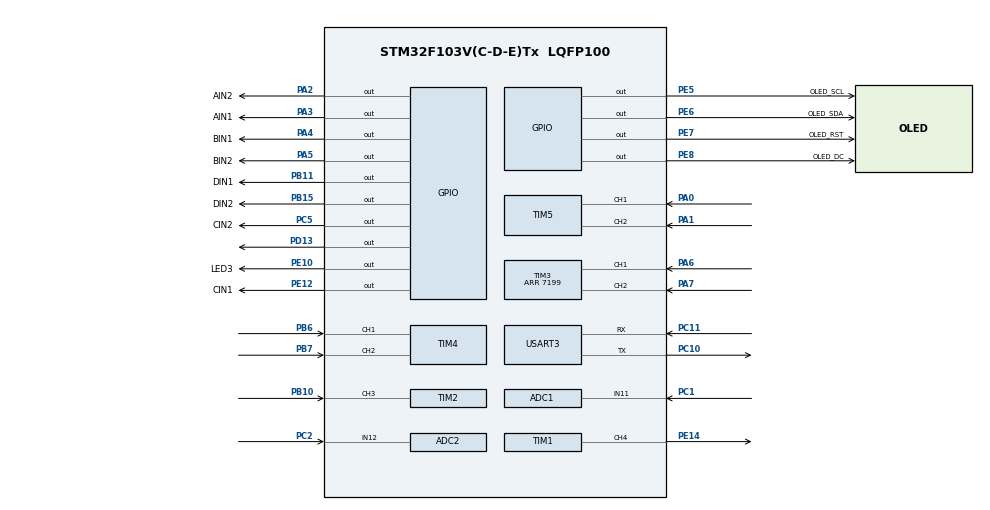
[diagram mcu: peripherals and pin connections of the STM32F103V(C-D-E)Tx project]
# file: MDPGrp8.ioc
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ADC1.Channel-1\#ChannelRegularConversion=ADC_CHANNEL_11
ADC1.NbrOfConversionFlag=1
ADC1.Rank-1\#ChannelRegularConversion=1
ADC1.SamplingTime-1\#ChannelRegularConversion=ADC_SAMPLETIME_1CYCLE_5
ADC1.master=1
ADC2.Channel-0\#ChannelRegularConversion=ADC_CHANNEL_12
ADC2.NbrOfConversionFlag=1
ADC2.Rank-0\#ChannelRegularConversion=1
ADC2.SamplingTime-0\#ChannelRegularConversion=ADC_SAMPLETIME_1CYCLE_5
FREERTOS.Tasks01=defaultTask,24,128,StartDefaultTask,Default,NULL,Dynamic,NULL,NULL;RightMotorTask,8,128,rightmotor,Default,NULL,Dynamic,NULL,NULL;LeftMotorTask,8,128,leftmotor,Default,NULL,Dynamic,NULL,NULL;SensorTask,8,128,sensor,Default,NULL,Dynamic,NULL,NULL
Mcu.Family=STM32F1
Mcu.Name=STM32F103V(C-D-E)Tx
Mcu.Package=LQFP100
NVIC.PriorityGroup=NVIC_PRIORITYGROUP_4
NVIC.TIM2_IRQn=true\:5\:0\:false\:false\:true\:true\:true\:true
NVIC.USART3_IRQn=true\:5\:0\:false\:false\:true\:true\:true\:true
OSC_IN.Mode=HSE-External-Oscillator
OSC_IN.Signal=RCC_OSC_IN
OSC_OUT.Mode=HSE-External-Oscillator
OSC_OUT.Signal=RCC_OSC_OUT
PA0-WKUP.Signal=S_TIM5_CH1
PA1.Signal=S_TIM5_CH2
PA13.Mode=Serial_Wire
PA13.Signal=SYS_JTMS-SWDIO
PA14.Mode=Serial_Wire
PA14.Signal=SYS_JTCK-SWCLK
PA2.GPIO_Label=AIN2
PA2.GPIO_Speed=GPIO_SPEED_FREQ_HIGH
PA2.Signal=GPIO_Output
PA3.GPIO_Label=AIN1
PA3.GPIO_Speed=GPIO_SPEED_FREQ_HIGH
PA3.Signal=GPIO_Output
PA4.GPIO_Label=BIN1
PA4.GPIO_Speed=GPIO_SPEED_FREQ_HIGH
PA4.Signal=GPIO_Output
PA5.GPIO_Label=BIN2
PA5.GPIO_Speed=GPIO_SPEED_FREQ_HIGH
PA5.Signal=GPIO_Output
PA6.Signal=S_TIM3_CH1
PA7.Signal=S_TIM3_CH2
PB10.Signal=S_TIM2_CH3
PB11.GPIO_Label=DIN1
PB11.GPIO_Speed=GPIO_SPEED_FREQ_HIGH
PB11.PinState=GPIO_PIN_RESET
PB11.Signal=GPIO_Output
PB15.GPIO_Label=DIN2
PB15.GPIO_Speed=GPIO_SPEED_FREQ_HIGH
PB15.PinState=GPIO_PIN_RESET
PB15.Signal=GPIO_Output
PB6.Signal=S_TIM4_CH1
PB7.Signal=S_TIM4_CH2
PC1.Signal=ADCx_IN11
PC10.Mode=Asynchronous
PC10.Signal=USART3_TX
PC11.Mode=Asynchronous
PC11.Signal=USART3_RX
PC14-OSC32_IN.Mode=LSE-External-Oscillator
PC14-OSC32_IN.Signal=RCC_OSC32_IN
PC15-OSC32_OUT.Mode=LSE-External-Oscillator
PC15-OSC32_OUT.Signal=RCC_OSC32_OUT
PC2.Signal=ADCx_IN12
PC5.GPIO_Label=CIN2
PC5.GPIO_Speed=GPIO_SPEED_FREQ_HIGH
PC5.Signal=GPIO_Output
PC6.GPIO_Label=TIM8_CH1
PC6.Signal=S_TIM8_CH1
PC7.GPIO_Label=TIM8_CH2
PC7.Signal=S_TIM8_CH2
PC8.Signal=S_TIM8_CH3
PC9.Signal=S_TIM8_CH4
PD13.Signal=GPIO_Output
PE10.GPIO_Label=LED3
PE10.Signal=GPIO_Output
PE12.GPIO_Label=CIN1
PE12.GPIO_Speed=GPIO_SPEED_FREQ_HIGH
PE12.Signal=GPIO_Output
PE14.Signal=S_TIM1_CH4
PE5.GPIO_Label=OLED_SCL
PE5.Signal=GPIO_Output
PE6.GPIO_Label=OLED_SDA
PE6.Signal=GPIO_Output
PE7.GPIO_Label=OLED_RST
PE7.Signal=GPIO_Output
PE8.GPIO_Label=OLED_DC
PE8.Signal=GPIO_Output
ProjectManager.HeapSize=0x200
ProjectManager.StackSize=0x400
ProjectManager.TargetToolchain=STM32CubeIDE
RCC.APB1Freq_Value=8000000
RCC.APB2Freq_Value=8000000
SH.ADCx_IN11.0=ADC1_IN11,IN11
SH.ADCx_IN12.0=ADC2_IN12,IN12
SH.S_TIM1_CH4.0=TIM1_CH4,PWM Generation4 CH4
SH.S_TIM2_CH3.0=TIM2_CH3,Input_Capture3_from_TI3
SH.S_TIM3_CH1.0=TIM3_CH1,Encoder_Interface
SH.S_TIM3_CH2.0=TIM3_CH2,Encoder_Interface
SH.S_TIM4_CH1.0=TIM4_CH1,Encoder_Interface
SH.S_TIM4_CH2.0=TIM4_CH2,Encoder_Interface
SH.S_TIM5_CH1.0=TIM5_CH1,Encoder_Interface
SH.S_TIM5_CH2.0=TIM5_CH2,Encoder_Interface
SH.S_TIM8_CH1.0=TIM8_CH1
SH.S_TIM8_CH2.0=TIM8_CH2
SH.S_TIM8_CH3.0=TIM8_CH3
SH.S_TIM8_CH4.0=TIM8_CH4
TIM1.AutoReloadPreload=TIM_AUTORELOAD_PRELOAD_ENABLE
TIM1.Channel-PWM\ Generation4\ CH4=TIM_CHANNEL_4
TIM1.Period=1000
TIM1.Prescaler=160
TIM2.Channel-Input_Capture3_from_TI3=TIM_CHANNEL_3
TIM2.Period=0xffff-1
TIM2.Prescaler=8-1
TIM3.EncoderMode=TIM_ENCODERMODE_TI12
TIM3.IC1Filter=10
TIM3.IC2Filter=10
TIM3.Period=7199
TIM4.EncoderMode=TIM_ENCODERMODE_TI12
TIM4.IC1Filter=10
TIM4.IC2Filter=10
TIM5.EncoderMode=TIM_ENCODERMODE_TI12
TIM5.IC1Filter=10
TIM5.IC2Filter=10
TIM8.Channel-PWM\ Generation1\ No\ Output=TIM_CHANNEL_1
TIM8.Channel-PWM\ Generation2\ No\ Output=TIM_CHANNEL_2
TIM8.Channel-PWM\ Generation3\ No\ Output=TIM_CHANNEL_3
TIM8.Channel-PWM\ Generation4\ No\ Output=TIM_CHANNEL_4
TIM8.Period=7199
USART3.VirtualMode=VM_ASYNC
VP_FREERTOS_VS_CMSIS_V2.Mode=CMSIS_V2
VP_TIM1_VS_ClockSourceINT.Mode=Internal
VP_TIM8_VS_ClockSourceINT.Mode=Internal
VP_TIM8_VS_no_output1.Mode=PWM Generation1 No Output
VP_TIM8_VS_no_output2.Mode=PWM Generation2 No Output
VP_TIM8_VS_no_output3.Mode=PWM Generation3 No Output
VP_TIM8_VS_no_output4.Mode=PWM Generation4 No Output
board=custom

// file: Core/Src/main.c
/* USER CODE BEGIN Header */
/**
  ******************************************************************************
  * @file           : main.c
  * @brief          : Main program body
  ******************************************************************************
  * @attention
  *
  * <h2><center>&copy; Copyright (c) 2021 STMicroelectronics.
  * All rights reserved.</center></h2>
  *
  * This software component is licensed by ST under BSD 3-Clause license,
  * the "License"; You may not use this file except in compliance with the
  * License. You may obtain a copy of the License at:
  *                        opensource.org/licenses/BSD-3-Clause
  *
  ******************************************************************************
  */
/* USER CODE END Header */
#include "main.h"
#include "cmsis_os.h"
#include "oled.h"
#include "stdio.h"

ADC_HandleTypeDef hadc1;
ADC_HandleTypeDef hadc2;

TIM_HandleTypeDef htim1;
TIM_HandleTypeDef htim2;
TIM_HandleTypeDef htim3;
TIM_HandleTypeDef htim4;
TIM_HandleTypeDef htim5;
TIM_HandleTypeDef htim8;

UART_HandleTypeDef huart3;

/* Definitions for defaultTask */
osThreadId_t defaultTaskHandle;
const osThreadAttr_t defaultTask_attributes = {
  .name = "defaultTask",
  .stack_size = 128 * 4,
  .priority = (osPriority_t) osPriorityNormal,
};
/* Definitions for RightMotorTask */
osThreadId_t RightMotorTaskHandle;
const osThreadAttr_t RightMotorTask_attributes = {
  .name = "RightMotorTask",
  .stack_size = 128 * 4,
  .priority = (osPriority_t) osPriorityLow,
};
/* Definitions for LeftMotorTask */
osThreadId_t LeftMotorTaskHandle;
const osThreadAttr_t LeftMotorTask_attributes = {
  .name = "LeftMotorTask",
  .stack_size = 128 * 4,
  .priority = (osPriority_t) osPriorityLow,
};
/* Definitions for SensorTask */
osThreadId_t SensorTaskHandle;
const osThreadAttr_t SensorTask_attributes = {
  .name = "SensorTask",
  .stack_size = 128 * 4,
  .priority = (osPriority_t) osPriorityLow,
};

void SystemClock_Config(void);
static void MX_GPIO_Init(void);
static void MX_TIM8_Init(void);
static void MX_TIM2_Init(void);
static void MX_TIM3_Init(void);
static void MX_TIM1_Init(void);
static void MX_USART3_UART_Init(void);
static void MX_TIM4_Init(void);
static void MX_TIM5_Init(void);
static void MX_ADC1_Init(void);
static void MX_ADC2_Init(void);
void StartDefaultTask(void *argument);
void rightmotor(void *argument);
void leftmotor(void *argument);
void sensor(void *argument);

/* USER CODE BEGIN 0 */
uint8_t aRxBuffer[5];
uint8_t value[5];
uint8_t home[5];
uint8_t stopwheel=0;
uint8_t sensordist;
uint8_t move5;
/* USER CODE END 0 */
void delay (uint16_t time)
{
	__HAL_TIM_SET_COUNTER(&htim2,0);
	while(__HAL_TIM_GET_COUNTER (&htim2)< time);
}

uint32_t IC_Val1 = 0;
uint32_t IC_Val2 = 0;
uint32_t Difference = 0;
uint8_t Is_First_Captured = 0;  // is the first value captured ?
uint8_t Distance  = 0;

#define TRIG_PIN GPIO_PIN_13
#define TRIG_PORT GPIOD

// Let's write the callback function

void HAL_TIM_IC_CaptureCallback(TIM_HandleTypeDef *htim)
{
	if (htim->Channel == HAL_TIM_ACTIVE_CHANNEL_3)  // if the interrupt source is channel1
	{
		if (Is_First_Captured==0) // if the first value is not captured
		{
			IC_Val1 = HAL_TIM_ReadCapturedValue(htim, TIM_CHANNEL_3); // read the first value
			Is_First_Captured = 1;  // set the first captured as true
			// Now change the polarity to falling edge
			__HAL_TIM_SET_CAPTUREPOLARITY(htim, TIM_CHANNEL_3, TIM_INPUTCHANNELPOLARITY_FALLING);
		}

		else if (Is_First_Captured==1)   // if the first is already captured
		{
			IC_Val2 = HAL_TIM_ReadCapturedValue(htim, TIM_CHANNEL_3);  // read second value
			__HAL_TIM_SET_COUNTER(htim, 0);  // reset the counter

			if (IC_Val2 > IC_Val1)
			{
				Difference = IC_Val2-IC_Val1;
			}

			else if (IC_Val1 > IC_Val2)
			{
				Difference = (0xffff - IC_Val1) + IC_Val2;
			}

			Distance = Difference * .034/2;
			Is_First_Captured = 0; // set it back to false

			// set polarity to rising edge
			__HAL_TIM_SET_CAPTUREPOLARITY(htim, TIM_CHANNEL_3, TIM_INPUTCHANNELPOLARITY_RISING);
			__HAL_TIM_DISABLE_IT(&htim2, TIM_IT_CC1);
		}
	}
}

void HCSR04_Read (void)
{
	HAL_GPIO_WritePin(TRIG_PORT, TRIG_PIN, GPIO_PIN_SET);  // pull the TRIG pin HIGH
	delay(10);  // wait for 10 us
	HAL_GPIO_WritePin(TRIG_PORT, TRIG_PIN, GPIO_PIN_RESET);  // pull the TRIG pin low

	__HAL_TIM_ENABLE_IT(&htim2, TIM_IT_CC1);
}
int main(void)
{

  /* MCU Configuration--------------------------------------------------------*/

  /* Reset of all peripherals, Initializes the Flash interface and the Systick. */
  HAL_Init();

  /* Configure the system clock */
  SystemClock_Config();

  /* Initialize all configured peripherals */
  MX_GPIO_Init();
  MX_TIM8_Init();
  MX_TIM2_Init();
  MX_TIM3_Init();
  MX_TIM1_Init();
  MX_USART3_UART_Init();
  MX_TIM4_Init();
  MX_TIM5_Init();
  MX_ADC1_Init();
  MX_ADC2_Init();
  /* USER CODE BEGIN 2 */
  OLED_Init();
  /* USER CODE END 2 */

  /* Init scheduler */
  osKernelInitialize();

  /* Create the thread(s) */
  /* creation of defaultTask */
  defaultTaskHandle = osThreadNew(StartDefaultTask, NULL, &defaultTask_attributes);

  /* creation of RightMotorTask */
  RightMotorTaskHandle = osThreadNew(rightmotor, NULL, &RightMotorTask_attributes);

  /* creation of LeftMotorTask */
  LeftMotorTaskHandle = osThreadNew(leftmotor, NULL, &LeftMotorTask_attributes);

  /* creation of SensorTask */
  SensorTaskHandle = osThreadNew(sensor, NULL, &SensorTask_attributes);

  /* Start scheduler */
  osKernelStart();

  /* We should never get here as control is now taken by the scheduler */
  /* Infinite loop */
  while (1)
  {

  }
}

void SystemClock_Config(void)
{
  RCC_OscInitTypeDef RCC_OscInitStruct = {0};
  RCC_ClkInitTypeDef RCC_ClkInitStruct = {0};
  RCC_PeriphCLKInitTypeDef PeriphClkInit = {0};

  /** Initializes the RCC Oscillators according to the specified parameters
  * in the RCC_OscInitTypeDef structure.
  */
  RCC_OscInitStruct.OscillatorType = RCC_OSCILLATORTYPE_HSI;
  RCC_OscInitStruct.HSIState = RCC_HSI_ON;
  RCC_OscInitStruct.HSICalibrationValue = RCC_HSICALIBRATION_DEFAULT;
  RCC_OscInitStruct.PLL.PLLState = RCC_PLL_NONE;
  if (HAL_RCC_OscConfig(&RCC_OscInitStruct) != HAL_OK)
  {
    Error_Handler();
  }
  /** Initializes the CPU, AHB and APB buses clocks
  */
  RCC_ClkInitStruct.ClockType = RCC_CLOCKTYPE_HCLK|RCC_CLOCKTYPE_SYSCLK
                              |RCC_CLOCKTYPE_PCLK1|RCC_CLOCKTYPE_PCLK2;
  RCC_ClkInitStruct.SYSCLKSource = RCC_SYSCLKSOURCE_HSI;
  RCC_ClkInitStruct.AHBCLKDivider = RCC_SYSCLK_DIV1;
  RCC_ClkInitStruct.APB1CLKDivider = RCC_HCLK_DIV1;
  RCC_ClkInitStruct.APB2CLKDivider = RCC_HCLK_DIV1;

  if (HAL_RCC_ClockConfig(&RCC_ClkInitStruct, FLASH_LATENCY_0) != HAL_OK)
  {
    Error_Handler();
  }
  PeriphClkInit.PeriphClockSelection = RCC_PERIPHCLK_ADC;
  PeriphClkInit.AdcClockSelection = RCC_ADCPCLK2_DIV2;
  if (HAL_RCCEx_PeriphCLKConfig(&PeriphClkInit) != HAL_OK)
  {
    Error_Handler();
  }
}

static void MX_ADC1_Init(void)
{

  ADC_ChannelConfTypeDef sConfig = {0};

  /** Common config
  */
  hadc1.Instance = ADC1;
  hadc1.Init.ScanConvMode = ADC_SCAN_DISABLE;
  hadc1.Init.ContinuousConvMode = DISABLE;
  hadc1.Init.DiscontinuousConvMode = DISABLE;
  hadc1.Init.ExternalTrigConv = ADC_SOFTWARE_START;
  hadc1.Init.DataAlign = ADC_DATAALIGN_RIGHT;
  hadc1.Init.NbrOfConversion = 1;
  if (HAL_ADC_Init(&hadc1) != HAL_OK)
  {
    Error_Handler();
  }
  /** Configure Regular Channel
  */
  sConfig.Channel = ADC_CHANNEL_11;
  sConfig.Rank = ADC_REGULAR_RANK_1;
  sConfig.SamplingTime = ADC_SAMPLETIME_1CYCLE_5;
  if (HAL_ADC_ConfigChannel(&hadc1, &sConfig) != HAL_OK)
  {
    Error_Handler();
  }

}

static void MX_ADC2_Init(void)
{

  ADC_ChannelConfTypeDef sConfig = {0};

  /** Common config
  */
  hadc2.Instance = ADC2;
  hadc2.Init.ScanConvMode = ADC_SCAN_DISABLE;
  hadc2.Init.ContinuousConvMode = DISABLE;
  hadc2.Init.DiscontinuousConvMode = DISABLE;
  hadc2.Init.ExternalTrigConv = ADC_SOFTWARE_START;
  hadc2.Init.DataAlign = ADC_DATAALIGN_RIGHT;
  hadc2.Init.NbrOfConversion = 1;
  if (HAL_ADC_Init(&hadc2) != HAL_OK)
  {
    Error_Handler();
  }
  /** Configure Regular Channel
  */
  sConfig.Channel = ADC_CHANNEL_12;
  sConfig.Rank = ADC_REGULAR_RANK_1;
  sConfig.SamplingTime = ADC_SAMPLETIME_1CYCLE_5;
  if (HAL_ADC_ConfigChannel(&hadc2, &sConfig) != HAL_OK)
  {
    Error_Handler();
  }

}

static void MX_TIM1_Init(void)
{

  TIM_ClockConfigTypeDef sClockSourceConfig = {0};
  TIM_MasterConfigTypeDef sMasterConfig = {0};
  TIM_OC_InitTypeDef sConfigOC = {0};
  TIM_BreakDeadTimeConfigTypeDef sBreakDeadTimeConfig = {0};

  htim1.Instance = TIM1;
  htim1.Init.Prescaler = 160;
  htim1.Init.CounterMode = TIM_COUNTERMODE_UP;
  htim1.Init.Period = 1000;
  htim1.Init.ClockDivision = TIM_CLOCKDIVISION_DIV1;
  htim1.Init.RepetitionCounter = 0;
  htim1.Init.AutoReloadPreload = TIM_AUTORELOAD_PRELOAD_ENABLE;
  if (HAL_TIM_Base_Init(&htim1) != HAL_OK)
  {
    Error_Handler();
  }
  sClockSourceConfig.ClockSource = TIM_CLOCKSOURCE_INTERNAL;
  if (HAL_TIM_ConfigClockSource(&htim1, &sClockSourceConfig) != HAL_OK)
  {
    Error_Handler();
  }
  if (HAL_TIM_PWM_Init(&htim1) != HAL_OK)
  {
    Error_Handler();
  }
  sMasterConfig.MasterOutputTrigger = TIM_TRGO_RESET;
  sMasterConfig.MasterSlaveMode = TIM_MASTERSLAVEMODE_DISABLE;
  if (HAL_TIMEx_MasterConfigSynchronization(&htim1, &sMasterConfig) != HAL_OK)
  {
    Error_Handler();
  }
  sConfigOC.OCMode = TIM_OCMODE_PWM1;
  sConfigOC.Pulse = 0;
  sConfigOC.OCPolarity = TIM_OCPOLARITY_HIGH;
  sConfigOC.OCFastMode = TIM_OCFAST_DISABLE;
  sConfigOC.OCIdleState = TIM_OCIDLESTATE_RESET;
  sConfigOC.OCNIdleState = TIM_OCNIDLESTATE_RESET;
  if (HAL_TIM_PWM_ConfigChannel(&htim1, &sConfigOC, TIM_CHANNEL_4) != HAL_OK)
  {
    Error_Handler();
  }
  sBreakDeadTimeConfig.OffStateRunMode = TIM_OSSR_DISABLE;
  sBreakDeadTimeConfig.OffStateIDLEMode = TIM_OSSI_DISABLE;
  sBreakDeadTimeConfig.LockLevel = TIM_LOCKLEVEL_OFF;
  sBreakDeadTimeConfig.DeadTime = 0;
  sBreakDeadTimeConfig.BreakState = TIM_BREAK_DISABLE;
  sBreakDeadTimeConfig.BreakPolarity = TIM_BREAKPOLARITY_HIGH;
  sBreakDeadTimeConfig.AutomaticOutput = TIM_AUTOMATICOUTPUT_DISABLE;
  if (HAL_TIMEx_ConfigBreakDeadTime(&htim1, &sBreakDeadTimeConfig) != HAL_OK)
  {
    Error_Handler();
  }
  HAL_TIM_MspPostInit(&htim1);

}

static void MX_TIM2_Init(void)
{

  TIM_MasterConfigTypeDef sMasterConfig = {0};
  TIM_IC_InitTypeDef sConfigIC = {0};

  htim2.Instance = TIM2;
  htim2.Init.Prescaler = 8-1;
  htim2.Init.CounterMode = TIM_COUNTERMODE_UP;
  htim2.Init.Period = 0xffff-1;
  htim2.Init.ClockDivision = TIM_CLOCKDIVISION_DIV1;
  htim2.Init.AutoReloadPreload = TIM_AUTORELOAD_PRELOAD_DISABLE;
  if (HAL_TIM_IC_Init(&htim2) != HAL_OK)
  {
    Error_Handler();
  }
  sMasterConfig.MasterOutputTrigger = TIM_TRGO_RESET;
  sMasterConfig.MasterSlaveMode = TIM_MASTERSLAVEMODE_DISABLE;
  if (HAL_TIMEx_MasterConfigSynchronization(&htim2, &sMasterConfig) != HAL_OK)
  {
    Error_Handler();
  }
  sConfigIC.ICPolarity = TIM_INPUTCHANNELPOLARITY_RISING;
  sConfigIC.ICSelection = TIM_ICSELECTION_DIRECTTI;
  sConfigIC.ICPrescaler = TIM_ICPSC_DIV1;
  sConfigIC.ICFilter = 0;
  if (HAL_TIM_IC_ConfigChannel(&htim2, &sConfigIC, TIM_CHANNEL_3) != HAL_OK)
  {
    Error_Handler();
  }

}

static void MX_TIM3_Init(void)
{

  TIM_Encoder_InitTypeDef sConfig = {0};
  TIM_MasterConfigTypeDef sMasterConfig = {0};

  htim3.Instance = TIM3;
  htim3.Init.Prescaler = 0;
  htim3.Init.CounterMode = TIM_COUNTERMODE_UP;
  htim3.Init.Period = 7199;
  htim3.Init.ClockDivision = TIM_CLOCKDIVISION_DIV1;
  htim3.Init.AutoReloadPreload = TIM_AUTORELOAD_PRELOAD_DISABLE;
  sConfig.EncoderMode = TIM_ENCODERMODE_TI12;
  sConfig.IC1Polarity = TIM_ICPOLARITY_RISING;
  sConfig.IC1Selection = TIM_ICSELECTION_DIRECTTI;
  sConfig.IC1Prescaler = TIM_ICPSC_DIV1;
  sConfig.IC1Filter = 10;
  sConfig.IC2Polarity = TIM_ICPOLARITY_RISING;
  sConfig.IC2Selection = TIM_ICSELECTION_DIRECTTI;
  sConfig.IC2Prescaler = TIM_ICPSC_DIV1;
  sConfig.IC2Filter = 10;
  if (HAL_TIM_Encoder_Init(&htim3, &sConfig) != HAL_OK)
  {
    Error_Handler();
  }
  sMasterConfig.MasterOutputTrigger = TIM_TRGO_RESET;
  sMasterConfig.MasterSlaveMode = TIM_MASTERSLAVEMODE_DISABLE;
  if (HAL_TIMEx_MasterConfigSynchronization(&htim3, &sMasterConfig) != HAL_OK)
  {
    Error_Handler();
  }

}

static void MX_TIM4_Init(void)
{

  TIM_Encoder_InitTypeDef sConfig = {0};
  TIM_MasterConfigTypeDef sMasterConfig = {0};

  htim4.Instance = TIM4;
  htim4.Init.Prescaler = 0;
  htim4.Init.CounterMode = TIM_COUNTERMODE_UP;
  htim4.Init.Period = 65535;
  htim4.Init.ClockDivision = TIM_CLOCKDIVISION_DIV1;
  htim4.Init.AutoReloadPreload = TIM_AUTORELOAD_PRELOAD_DISABLE;
  sConfig.EncoderMode = TIM_ENCODERMODE_TI12;
  sConfig.IC1Polarity = TIM_ICPOLARITY_RISING;
  sConfig.IC1Selection = TIM_ICSELECTION_DIRECTTI;
  sConfig.IC1Prescaler = TIM_ICPSC_DIV1;
  sConfig.IC1Filter = 10;
  sConfig.IC2Polarity = TIM_ICPOLARITY_RISING;
  sConfig.IC2Selection = TIM_ICSELECTION_DIRECTTI;
  sConfig.IC2Prescaler = TIM_ICPSC_DIV1;
  sConfig.IC2Filter = 10;
  if (HAL_TIM_Encoder_Init(&htim4, &sConfig) != HAL_OK)
  {
    Error_Handler();
  }
  sMasterConfig.MasterOutputTrigger = TIM_TRGO_RESET;
  sMasterConfig.MasterSlaveMode = TIM_MASTERSLAVEMODE_DISABLE;
  if (HAL_TIMEx_MasterConfigSynchronization(&htim4, &sMasterConfig) != HAL_OK)
  {
    Error_Handler();
  }

}

static void MX_TIM5_Init(void)
{

  TIM_Encoder_InitTypeDef sConfig = {0};
  TIM_MasterConfigTypeDef sMasterConfig = {0};

  htim5.Instance = TIM5;
  htim5.Init.Prescaler = 0;
  htim5.Init.CounterMode = TIM_COUNTERMODE_UP;
  htim5.Init.Period = 65535;
  htim5.Init.ClockDivision = TIM_CLOCKDIVISION_DIV1;
  htim5.Init.AutoReloadPreload = TIM_AUTORELOAD_PRELOAD_DISABLE;
  sConfig.EncoderMode = TIM_ENCODERMODE_TI12;
  sConfig.IC1Polarity = TIM_ICPOLARITY_RISING;
  sConfig.IC1Selection = TIM_ICSELECTION_DIRECTTI;
  sConfig.IC1Prescaler = TIM_ICPSC_DIV1;
  sConfig.IC1Filter = 10;
  sConfig.IC2Polarity = TIM_ICPOLARITY_RISING;
  sConfig.IC2Selection = TIM_ICSELECTION_DIRECTTI;
  sConfig.IC2Prescaler = TIM_ICPSC_DIV1;
  sConfig.IC2Filter = 10;
  if (HAL_TIM_Encoder_Init(&htim5, &sConfig) != HAL_OK)
  {
    Error_Handler();
  }
  sMasterConfig.MasterOutputTrigger = TIM_TRGO_RESET;
  sMasterConfig.MasterSlaveMode = TIM_MASTERSLAVEMODE_DISABLE;
  if (HAL_TIMEx_MasterConfigSynchronization(&htim5, &sMasterConfig) != HAL_OK)
  {
    Error_Handler();
  }

}

static void MX_TIM8_Init(void)
{

  TIM_ClockConfigTypeDef sClockSourceConfig = {0};
  TIM_MasterConfigTypeDef sMasterConfig = {0};
  TIM_OC_InitTypeDef sConfigOC = {0};
  TIM_BreakDeadTimeConfigTypeDef sBreakDeadTimeConfig = {0};

  htim8.Instance = TIM8;
  htim8.Init.Prescaler = 0;
  htim8.Init.CounterMode = TIM_COUNTERMODE_UP;
  htim8.Init.Period = 7199;
  htim8.Init.ClockDivision = TIM_CLOCKDIVISION_DIV1;
  htim8.Init.RepetitionCounter = 0;
  htim8.Init.AutoReloadPreload = TIM_AUTORELOAD_PRELOAD_DISABLE;
  if (HAL_TIM_Base_Init(&htim8) != HAL_OK)
  {
    Error_Handler();
  }
  sClockSourceConfig.ClockSource = TIM_CLOCKSOURCE_INTERNAL;
  if (HAL_TIM_ConfigClockSource(&htim8, &sClockSourceConfig) != HAL_OK)
  {
    Error_Handler();
  }
  if (HAL_TIM_PWM_Init(&htim8) != HAL_OK)
  {
    Error_Handler();
  }
  sMasterConfig.MasterOutputTrigger = TIM_TRGO_RESET;
  sMasterConfig.MasterSlaveMode = TIM_MASTERSLAVEMODE_DISABLE;
  if (HAL_TIMEx_MasterConfigSynchronization(&htim8, &sMasterConfig) != HAL_OK)
  {
    Error_Handler();
  }
  sConfigOC.OCMode = TIM_OCMODE_PWM1;
  sConfigOC.Pulse = 0;
  sConfigOC.OCPolarity = TIM_OCPOLARITY_HIGH;
  sConfigOC.OCNPolarity = TIM_OCNPOLARITY_HIGH;
  sConfigOC.OCFastMode = TIM_OCFAST_DISABLE;
  sConfigOC.OCIdleState = TIM_OCIDLESTATE_RESET;
  sConfigOC.OCNIdleState = TIM_OCNIDLESTATE_RESET;
  if (HAL_TIM_PWM_ConfigChannel(&htim8, &sConfigOC, TIM_CHANNEL_1) != HAL_OK)
  {
    Error_Handler();
  }
  if (HAL_TIM_PWM_ConfigChannel(&htim8, &sConfigOC, TIM_CHANNEL_2) != HAL_OK)
  {
    Error_Handler();
  }
  if (HAL_TIM_PWM_ConfigChannel(&htim8, &sConfigOC, TIM_CHANNEL_3) != HAL_OK)
  {
    Error_Handler();
  }
  if (HAL_TIM_PWM_ConfigChannel(&htim8, &sConfigOC, TIM_CHANNEL_4) != HAL_OK)
  {
    Error_Handler();
  }
  sBreakDeadTimeConfig.OffStateRunMode = TIM_OSSR_DISABLE;
  sBreakDeadTimeConfig.OffStateIDLEMode = TIM_OSSI_DISABLE;
  sBreakDeadTimeConfig.LockLevel = TIM_LOCKLEVEL_OFF;
  sBreakDeadTimeConfig.DeadTime = 0;
  sBreakDeadTimeConfig.BreakState = TIM_BREAK_DISABLE;
  sBreakDeadTimeConfig.BreakPolarity = TIM_BREAKPOLARITY_HIGH;
  sBreakDeadTimeConfig.AutomaticOutput = TIM_AUTOMATICOUTPUT_DISABLE;
  if (HAL_TIMEx_ConfigBreakDeadTime(&htim8, &sBreakDeadTimeConfig) != HAL_OK)
  {
    Error_Handler();
  }

}

static void MX_USART3_UART_Init(void)
{

  huart3.Instance = USART3;
  huart3.Init.BaudRate = 115200;
  huart3.Init.WordLength = UART_WORDLENGTH_8B;
  huart3.Init.StopBits = UART_STOPBITS_1;
  huart3.Init.Parity = UART_PARITY_NONE;
  huart3.Init.Mode = UART_MODE_TX_RX;
  huart3.Init.HwFlowCtl = UART_HWCONTROL_NONE;
  huart3.Init.OverSampling = UART_OVERSAMPLING_16;
  if (HAL_UART_Init(&huart3) != HAL_OK)
  {
    Error_Handler();
  }

}

static void MX_GPIO_Init(void)
{
  GPIO_InitTypeDef GPIO_InitStruct = {0};

  /* GPIO Ports Clock Enable */
  __HAL_RCC_GPIOE_CLK_ENABLE();
  __HAL_RCC_GPIOC_CLK_ENABLE();
  __HAL_RCC_GPIOA_CLK_ENABLE();
  __HAL_RCC_GPIOB_CLK_ENABLE();
  __HAL_RCC_GPIOD_CLK_ENABLE();

  /*Configure GPIO pin Output Level */
  HAL_GPIO_WritePin(GPIOE, OLED_SCL_Pin|OLED_SDA_Pin|OLED_RST_Pin|OLED_DC_Pin
                          |LED3_Pin|CIN1_Pin, GPIO_PIN_RESET);

  /*Configure GPIO pin Output Level */
  HAL_GPIO_WritePin(GPIOA, AIN2_Pin|AIN1_Pin|BIN1_Pin|BIN2_Pin, GPIO_PIN_RESET);

  /*Configure GPIO pin Output Level */
  HAL_GPIO_WritePin(CIN2_GPIO_Port, CIN2_Pin, GPIO_PIN_RESET);

  /*Configure GPIO pin Output Level */
  HAL_GPIO_WritePin(GPIOB, DIN1_Pin|DIN2_Pin, GPIO_PIN_RESET);

  /*Configure GPIO pin Output Level */
  HAL_GPIO_WritePin(GPIOD, GPIO_PIN_13, GPIO_PIN_RESET);

  /*Configure GPIO pins : OLED_SCL_Pin OLED_SDA_Pin OLED_RST_Pin OLED_DC_Pin
                           LED3_Pin */
  GPIO_InitStruct.Pin = OLED_SCL_Pin|OLED_SDA_Pin|OLED_RST_Pin|OLED_DC_Pin
                          |LED3_Pin;
  GPIO_InitStruct.Mode = GPIO_MODE_OUTPUT_PP;
  GPIO_InitStruct.Pull = GPIO_NOPULL;
  GPIO_InitStruct.Speed = GPIO_SPEED_FREQ_LOW;
  HAL_GPIO_Init(GPIOE, &GPIO_InitStruct);

  /*Configure GPIO pins : AIN2_Pin AIN1_Pin BIN1_Pin BIN2_Pin */
  GPIO_InitStruct.Pin = AIN2_Pin|AIN1_Pin|BIN1_Pin|BIN2_Pin;
  GPIO_InitStruct.Mode = GPIO_MODE_OUTPUT_PP;
  GPIO_InitStruct.Pull = GPIO_NOPULL;
  GPIO_InitStruct.Speed = GPIO_SPEED_FREQ_HIGH;
  HAL_GPIO_Init(GPIOA, &GPIO_InitStruct);

  /*Configure GPIO pin : CIN2_Pin */
  GPIO_InitStruct.Pin = CIN2_Pin;
  GPIO_InitStruct.Mode = GPIO_MODE_OUTPUT_PP;
  GPIO_InitStruct.Pull = GPIO_NOPULL;
  GPIO_InitStruct.Speed = GPIO_SPEED_FREQ_HIGH;
  HAL_GPIO_Init(CIN2_GPIO_Port, &GPIO_InitStruct);

  /*Configure GPIO pin : CIN1_Pin */
  GPIO_InitStruct.Pin = CIN1_Pin;
  GPIO_InitStruct.Mode = GPIO_MODE_OUTPUT_PP;
  GPIO_InitStruct.Pull = GPIO_NOPULL;
  GPIO_InitStruct.Speed = GPIO_SPEED_FREQ_HIGH;
  HAL_GPIO_Init(CIN1_GPIO_Port, &GPIO_InitStruct);

  /*Configure GPIO pins : DIN1_Pin DIN2_Pin */
  GPIO_InitStruct.Pin = DIN1_Pin|DIN2_Pin;
  GPIO_InitStruct.Mode = GPIO_MODE_OUTPUT_PP;
  GPIO_InitStruct.Pull = GPIO_NOPULL;
  GPIO_InitStruct.Speed = GPIO_SPEED_FREQ_HIGH;
  HAL_GPIO_Init(GPIOB, &GPIO_InitStruct);

  /*Configure GPIO pin : PD13 */
  GPIO_InitStruct.Pin = GPIO_PIN_13;
  GPIO_InitStruct.Mode = GPIO_MODE_OUTPUT_PP;
  GPIO_InitStruct.Pull = GPIO_NOPULL;
  GPIO_InitStruct.Speed = GPIO_SPEED_FREQ_LOW;
  HAL_GPIO_Init(GPIOD, &GPIO_InitStruct);

}

/* USER CODE BEGIN 4 */
void HAL_UART_RxCpltCallback(UART_HandleTypeDef *huart)
{
	UNUSED(huart);

	//HAL_UART_Transmit(&huart3, (uint8_t *)aRxBuffer,12,0xFFFF);
}
/* USER CODE END 4 */

void StartDefaultTask(void *argument)
{
  /* USER CODE BEGIN 5 */
  /* Infinite loop */
	uint8_t hello[20]="Hello World!\0";

	HAL_TIM_PWM_Start(&htim1,TIM_CHANNEL_4);
	uint8_t ch='A';
	sprintf(value,"%s\0","00000");
	int wk9task=0;

	uint8_t temp[5];
  for(;;)
  {	/*
	  htim1.Instance->CCR4=85;//right
	  osDelay(5000);
	  htim1.Instance->CCR4=72;//center
	  osDelay(5000);
	  htim1.Instance->CCR4=60;//left
	  osDelay(5000);
	  htim1.Instance->CCR4=72;//center
	  osDelay(5000);
	*/
	HAL_UART_Receive_IT(&huart3,(uint8_t *) aRxBuffer,5);
	OLED_ShowString(10,10,hello);
	sprintf(value,"%s\0",aRxBuffer);
	OLED_ShowString(10,40,value);
	HAL_GPIO_TogglePin(LED3_GPIO_Port,LED3_Pin);
	OLED_Refresh_Gram();
	osDelay(500);

  }
  /* USER CODE END 5 */
}

void rightmotor(void *argument)
{
  /* USER CODE BEGIN rightmotor */
  /* Infinite loop */
	uint16_t pwmVal=2900;
	HAL_TIM_PWM_Start(&htim8,TIM_CHANNEL_4);
	int x;
	uint8_t flag=1;

	uint32_t val=0;
	val=1.25*750;
	int backdistance;
	HAL_TIM_Encoder_Start(&htim5,TIM_CHANNEL_ALL);
	int cnt1,cnt2,diff;
	uint32_t tick;
	uint16_t dir;
	uint32_t tickbaseval=520;
	uint32_t totaldist=0;
	uint32_t dist=0;
	uint32_t temp;
	uint8_t hello[20];
	for(;;)
	{

		x=atoi(value);
		dist = (uint32_t)(x%1000); //Get last 2 Digit
		x/=1000;
		switch(x) {
			case 30	:

				totaldist=0;
				diff=0;
				cnt1=__HAL_TIM_GET_COUNTER(&htim5);
				htim1.Instance->CCR4=74;
				HAL_GPIO_WritePin(GPIOB, DIN2_Pin, GPIO_PIN_SET);
				HAL_GPIO_WritePin(GPIOB, DIN1_Pin, GPIO_PIN_RESET);
				__HAL_TIM_SetCompare(&htim8, TIM_CHANNEL_4, pwmVal);
				tick=HAL_GetTick();
				temp=sensordist/10;
				backdistance=temp;
				temp=tickbaseval*(temp-5);
				if(backdistance>=8)
				{
					while(totaldist<temp)
					{
//						if(sensordist<=37)
//						{
//							break;
//						}
						if(HAL_GetTick()-tick>25L)
						{
							cnt2=__HAL_TIM_GET_COUNTER(&htim5);
							if(__HAL_TIM_IS_TIM_COUNTING_DOWN(&htim5))
							{
								if(cnt2<cnt1)
									diff=cnt1-cnt2;
								else
									diff=(65535-cnt2)+cnt1;
							}
							else
							{
								if(cnt2>cnt1)
									diff=cnt2-cnt1;
								else
									diff=(65535-cnt1)+cnt2;
							}

							sprintf(hello, "S:%5d\0", diff);
							OLED_ShowString(50,30,hello);
							dir = __HAL_TIM_IS_TIM_COUNTING_DOWN(&htim5);
							sprintf(hello, "RD:%2d\0", dir);
							OLED_ShowString(10,30,hello);
							cnt1=__HAL_TIM_GET_COUNTER(&htim5);
							tick=HAL_GetTick();
							totaldist+=diff;
						}

					}
				}
				else
				{
					while(totaldist<temp)
					{
						if(sensordist<=37)
						{
							break;
						}
						if(HAL_GetTick()-tick>25L)
						{
							cnt2=__HAL_TIM_GET_COUNTER(&htim5);
							if(__HAL_TIM_IS_TIM_COUNTING_DOWN(&htim5))
							{
								if(cnt2<cnt1)
									diff=cnt1-cnt2;
								else
									diff=(65535-cnt2)+cnt1;
							}
							else
							{
								if(cnt2>cnt1)
									diff=cnt2-cnt1;
								else
									diff=(65535-cnt1)+cnt2;
							}

							sprintf(hello, "S:%5d\0", diff);
							OLED_ShowString(50,30,hello);
							dir = __HAL_TIM_IS_TIM_COUNTING_DOWN(&htim5);
							sprintf(hello, "RD:%2d\0", dir);
							OLED_ShowString(10,30,hello);
							cnt1=__HAL_TIM_GET_COUNTER(&htim5);
							tick=HAL_GetTick();
							totaldist+=diff;
						}

					}

				}
				__HAL_TIM_SetCompare(&htim8, TIM_CHANNEL_4, 0);

					htim1.Instance->CCR4=74;
					HAL_GPIO_WritePin(GPIOB, DIN2_Pin, GPIO_PIN_SET);
					HAL_GPIO_WritePin(GPIOB, DIN1_Pin, GPIO_PIN_RESET);
					for(int i=0; i<3;i++)
					{
						while(sensordist>=37 )
						{
							__HAL_TIM_SetCompare(&htim8, TIM_CHANNEL_4, pwmVal);
							osDelay(50);
						}
					}

					__HAL_TIM_SetCompare(&htim8, TIM_CHANNEL_4, 0);

					flag=1;
					break;

			case 40	:

				totaldist=0;
				diff=0;
				cnt1=__HAL_TIM_GET_COUNTER(&htim5);
				htim1.Instance->CCR4=74;
				HAL_GPIO_WritePin(GPIOB, DIN2_Pin, GPIO_PIN_SET);
				HAL_GPIO_WritePin(GPIOB, DIN1_Pin, GPIO_PIN_RESET);
				__HAL_TIM_SetCompare(&htim8, TIM_CHANNEL_4, pwmVal);
				tick=HAL_GetTick();
				temp=backdistance-2;
				temp=tickbaseval*(temp-5);
				if(backdistance>=8)
				{
					while(totaldist<temp)
					{
//						if(sensordist<=25)
//						{
//							break;
//						}
						if(HAL_GetTick()-tick>25L)
						{
							cnt2=__HAL_TIM_GET_COUNTER(&htim5);
							if(__HAL_TIM_IS_TIM_COUNTING_DOWN(&htim5))
							{
								if(cnt2<cnt1)
									diff=cnt1-cnt2;
								else
									diff=(65535-cnt2)+cnt1;
							}
							else
							{
								if(cnt2>cnt1)
									diff=cnt2-cnt1;
								else
									diff=(65535-cnt1)+cnt2;
							}

							sprintf(hello, "S:%5d\0", diff);
							OLED_ShowString(50,30,hello);
							dir = __HAL_TIM_IS_TIM_COUNTING_DOWN(&htim5);
							sprintf(hello, "RD:%2d\0", dir);
							OLED_ShowString(10,30,hello);
							cnt1=__HAL_TIM_GET_COUNTER(&htim5);
							tick=HAL_GetTick();
							totaldist+=diff;
						}

					}
				}
				__HAL_TIM_SetCompare(&htim8, TIM_CHANNEL_4, 0);

					htim1.Instance->CCR4=74;
					HAL_GPIO_WritePin(GPIOB, DIN2_Pin, GPIO_PIN_SET);
					HAL_GPIO_WritePin(GPIOB, DIN1_Pin, GPIO_PIN_RESET);
					for(int i=0; i<3;i++)
					{
						while(sensordist>=25 )
						{
							__HAL_TIM_SetCompare(&htim8, TIM_CHANNEL_4, pwmVal);
							osDelay(50);
						}
					}

					__HAL_TIM_SetCompare(&htim8, TIM_CHANNEL_4, 0);

					flag=1;
					break;

			case 50	:

				totaldist=0;
				diff=0;
				cnt1=__HAL_TIM_GET_COUNTER(&htim5);
				htim1.Instance->CCR4=74;
				HAL_GPIO_WritePin(GPIOB, DIN2_Pin, GPIO_PIN_SET);
				HAL_GPIO_WritePin(GPIOB, DIN1_Pin, GPIO_PIN_RESET);
				__HAL_TIM_SetCompare(&htim8, TIM_CHANNEL_4, 4800);
				tick=HAL_GetTick();
				temp=sensordist/10;
				backdistance=temp;
				temp=tickbaseval*(temp-5);
				if(backdistance>=8)
				{
					while(totaldist<temp)
					{

						if(HAL_GetTick()-tick>25L)
						{
							cnt2=__HAL_TIM_GET_COUNTER(&htim5);
							if(__HAL_TIM_IS_TIM_COUNTING_DOWN(&htim5))
							{
								if(cnt2<cnt1)
									diff=cnt1-cnt2;
								else
									diff=(65535-cnt2)+cnt1;
							}
							else
							{
								if(cnt2>cnt1)
									diff=cnt2-cnt1;
								else
									diff=(65535-cnt1)+cnt2;
							}

							sprintf(hello, "S:%5d\0", diff);
							OLED_ShowString(50,30,hello);
							dir = __HAL_TIM_IS_TIM_COUNTING_DOWN(&htim5);
							sprintf(hello, "RD:%2d\0", dir);
							OLED_ShowString(10,30,hello);
							cnt1=__HAL_TIM_GET_COUNTER(&htim5);
							tick=HAL_GetTick();
							totaldist+=diff;
						}

					}
				}
				else
				{
					while(totaldist<temp)
					{
						if(sensordist<=37)
						{
							break;
						}
						if(HAL_GetTick()-tick>25L)
						{
							cnt2=__HAL_TIM_GET_COUNTER(&htim5);
							if(__HAL_TIM_IS_TIM_COUNTING_DOWN(&htim5))
							{
								if(cnt2<cnt1)
									diff=cnt1-cnt2;
								else
									diff=(65535-cnt2)+cnt1;
							}
							else
							{
								if(cnt2>cnt1)
									diff=cnt2-cnt1;
								else
									diff=(65535-cnt1)+cnt2;
							}

							sprintf(hello, "S:%5d\0", diff);
							OLED_ShowString(50,30,hello);
							dir = __HAL_TIM_IS_TIM_COUNTING_DOWN(&htim5);
							sprintf(hello, "RD:%2d\0", dir);
							OLED_ShowString(10,30,hello);
							cnt1=__HAL_TIM_GET_COUNTER(&htim5);
							tick=HAL_GetTick();
							totaldist+=diff;
						}

					}

				}
				__HAL_TIM_SetCompare(&htim8, TIM_CHANNEL_4, 0);

					htim1.Instance->CCR4=74;
					HAL_GPIO_WritePin(GPIOB, DIN2_Pin, GPIO_PIN_SET);
					HAL_GPIO_WritePin(GPIOB, DIN1_Pin, GPIO_PIN_RESET);
					for(int i=0; i<3;i++)
					{
						while(sensordist>=37 )
						{
							__HAL_TIM_SetCompare(&htim8, TIM_CHANNEL_4, 4800);
							osDelay(50);
						}
					}

					__HAL_TIM_SetCompare(&htim8, TIM_CHANNEL_4, 0);

					flag=1;
					break;

			case 60	:

				totaldist=0;
				diff=0;
				cnt1=__HAL_TIM_GET_COUNTER(&htim5);
				htim1.Instance->CCR4=74;
				HAL_GPIO_WritePin(GPIOB, DIN2_Pin, GPIO_PIN_SET);
				HAL_GPIO_WritePin(GPIOB, DIN1_Pin, GPIO_PIN_RESET);
				__HAL_TIM_SetCompare(&htim8, TIM_CHANNEL_4, 4800);
				tick=HAL_GetTick();
				temp=backdistance-2;
				temp=tickbaseval*(temp-5);
				if(backdistance>=8)
				{
					while(totaldist<temp)
					{

						if(HAL_GetTick()-tick>25L)
						{
							cnt2=__HAL_TIM_GET_COUNTER(&htim5);
							if(__HAL_TIM_IS_TIM_COUNTING_DOWN(&htim5))
							{
								if(cnt2<cnt1)
									diff=cnt1-cnt2;
								else
									diff=(65535-cnt2)+cnt1;
							}
							else
							{
								if(cnt2>cnt1)
									diff=cnt2-cnt1;
								else
									diff=(65535-cnt1)+cnt2;
							}

							sprintf(hello, "S:%5d\0", diff);
							OLED_ShowString(50,30,hello);
							dir = __HAL_TIM_IS_TIM_COUNTING_DOWN(&htim5);
							sprintf(hello, "RD:%2d\0", dir);
							OLED_ShowString(10,30,hello);
							cnt1=__HAL_TIM_GET_COUNTER(&htim5);
							tick=HAL_GetTick();
							totaldist+=diff;
						}

					}
				}
				__HAL_TIM_SetCompare(&htim8, TIM_CHANNEL_4, 0);

					htim1.Instance->CCR4=74;
					HAL_GPIO_WritePin(GPIOB, DIN2_Pin, GPIO_PIN_SET);
					HAL_GPIO_WritePin(GPIOB, DIN1_Pin, GPIO_PIN_RESET);
					for(int i=0; i<3;i++)
					{
						while(sensordist>=25 )
						{
							__HAL_TIM_SetCompare(&htim8, TIM_CHANNEL_4, 4800);
							osDelay(50);
						}
					}

					__HAL_TIM_SetCompare(&htim8, TIM_CHANNEL_4, 0);

					flag=1;
					break;

			case 18: //Turn Left 180
					htim1.Instance->CCR4=58;

					totaldist=0;
					diff=0;
					cnt1=__HAL_TIM_GET_COUNTER(&htim5);
					HAL_GPIO_WritePin(GPIOB, DIN2_Pin, GPIO_PIN_SET);
					HAL_GPIO_WritePin(GPIOB, DIN1_Pin, GPIO_PIN_RESET);
					__HAL_TIM_SetCompare(&htim8, TIM_CHANNEL_4, 2500);
					tick=HAL_GetTick();
					temp=tickbaseval*9.5;//5.4 5.2 for scse lounge 5.3 corridor
					while(totaldist<temp)
					{
						if(HAL_GetTick()-tick>50L)
						{
							cnt2=__HAL_TIM_GET_COUNTER(&htim5);
							if(__HAL_TIM_IS_TIM_COUNTING_DOWN(&htim5))
							{
								if(cnt2<cnt1)
									diff=cnt1-cnt2;
								else
									diff=(65535-cnt2)+cnt1;
							}
							else
							{
								if(cnt2>cnt1)
									diff=cnt2-cnt1;
								else
									diff=(65535-cnt1)+cnt2;
			}

			sprintf(hello, "S:%5d\0", diff);
			OLED_ShowString(50,30,hello);
			dir = __HAL_TIM_IS_TIM_COUNTING_DOWN(&htim5);
			sprintf(hello, "RD:%2d\0", dir);
			OLED_ShowString(10,30,hello);
			cnt1=__HAL_TIM_GET_COUNTER(&htim5);
			tick=HAL_GetTick();
			totaldist+=diff;
			}

			}

			__HAL_TIM_SetCompare(&htim8, TIM_CHANNEL_4, 0);
			flag=1;
			break;

			case 10 :

		    	/*htim1.Instance->CCR4=75;
				HAL_GPIO_WritePin(GPIOB, DIN2_Pin, GPIO_PIN_SET);
				HAL_GPIO_WritePin(GPIOB, DIN1_Pin, GPIO_PIN_RESET);
				__HAL_TIM_SetCompare(&htim8, TIM_CHANNEL_4, pwmVal);
				dist=dist*700;
				osDelay(dist);
				__HAL_TIM_SetCompare(&htim8, TIM_CHANNEL_4, 0);
				osDelay(200);
				if(dist==700)
				{
					osDelay(1000);
				}*/

				totaldist=0;
				diff=0;
				cnt1=__HAL_TIM_GET_COUNTER(&htim5);
				htim1.Instance->CCR4=74;
				HAL_GPIO_WritePin(GPIOB, DIN2_Pin, GPIO_PIN_SET);
				HAL_GPIO_WritePin(GPIOB, DIN1_Pin, GPIO_PIN_RESET);
				__HAL_TIM_SetCompare(&htim8, TIM_CHANNEL_4, pwmVal);
				tick=HAL_GetTick();
				temp=tickbaseval*dist*0.85;
				while(totaldist<temp)
				{
					if(HAL_GetTick()-tick>25L)
					{
						cnt2=__HAL_TIM_GET_COUNTER(&htim5);
						if(__HAL_TIM_IS_TIM_COUNTING_DOWN(&htim5))
						{
							if(cnt2<cnt1)
								diff=cnt1-cnt2;
							else
								diff=(65535-cnt2)+cnt1;
						}
						else
						{
							if(cnt2>cnt1)
								diff=cnt2-cnt1;
							else
								diff=(65535-cnt1)+cnt2;
						}

						sprintf(hello, "S:%5d\0", diff);
						OLED_ShowString(50,30,hello);
						dir = __HAL_TIM_IS_TIM_COUNTING_DOWN(&htim5);
						sprintf(hello, "RD:%2d\0", dir);
						OLED_ShowString(10,30,hello);
						cnt1=__HAL_TIM_GET_COUNTER(&htim5);
						tick=HAL_GetTick();
						totaldist+=diff;
					}

				}
				__HAL_TIM_SetCompare(&htim8, TIM_CHANNEL_4, 0);
/*				osDelay(200);
				htim1.Instance->CCR4=85;
				osDelay(500);
				htim1.Instance->CCR4=60;
				osDelay(500);
				htim1.Instance->CCR4=77;*/
				if(dist==1 || dist==2)
				{
				osDelay(1000);
				}
				flag=1;
				break;

/*				cnt2=__HAL_TIM_GET_COUNTER(&htim5);
				if(__HAL_TIM_IS_TIM_COUNTING_DOWN(&htim5))
				{
						if(cnt2<cnt1)
							diff=cnt1-cnt2;
						else
							diff=(65535-cnt2)+cnt1;
				}
				else
				{
						if(cnt2>cnt1)
							diff=cnt2-cnt1;
						else
							diff=(65535-cnt1)+cnt2;
				}
						//sprintf(hello, "S:%5d\0", diff);
						//OLED_ShowString(50,30,hello);
						//dir = __HAL_TIM_IS_TIM_COUNTING_DOWN(&htim5);
						//sprintf(hello, "RD:%2d\0", dir);
						//OLED_ShowString(10,30,hello);
						cnt1=__HAL_TIM_GET_COUNTER(&htim5);
						//tick=HAL_GetTick();

				__HAL_TIM_SetCompare(&htim8, TIM_CHANNEL_4, 0);
				if (diff>5000)
				{
					__HAL_TIM_SetCompare(&htim8, TIM_CHANNEL_4, 0);
					break;
				}*/

				//break;

		     case 11  :
/*		    	 	 	HAL_GPIO_WritePin(GPIOB, DIN2_Pin, GPIO_PIN_SET);
		    	 		HAL_GPIO_WritePin(GPIOB, DIN1_Pin, GPIO_PIN_RESET);
		    	 	    __HAL_TIM_SetCompare(&htim8, TIM_CHANNEL_4, pwmVal);
		    	 	    osDelay(val);*/

		    	 	 stopwheel=1;

/*					totaldist=0;
					diff=0;
					cnt1=__HAL_TIM_GET_COUNTER(&htim5);
					htim1.Instance->CCR4=74;
					HAL_GPIO_WritePin(GPIOB, DIN2_Pin, GPIO_PIN_SET);
					HAL_GPIO_WritePin(GPIOB, DIN1_Pin, GPIO_PIN_RESET);
					__HAL_TIM_SetCompare(&htim8, TIM_CHANNEL_4, pwmVal);
					tick=HAL_GetTick();
					temp=tickbaseval*0.8;
					while(totaldist<temp)
					{
						if(HAL_GetTick()-tick>50L)
						{
							cnt2=__HAL_TIM_GET_COUNTER(&htim5);
							if(__HAL_TIM_IS_TIM_COUNTING_DOWN(&htim5))
							{
								if(cnt2<cnt1)
									diff=cnt1-cnt2;
								else
									diff=(65535-cnt2)+cnt1;
							}
							else
							{
								if(cnt2>cnt1)
									diff=cnt2-cnt1;
								else
									diff=(65535-cnt1)+cnt2;
							}

							sprintf(hello, "S:%5d\0", diff);
							OLED_ShowString(50,30,hello);
							dir = __HAL_TIM_IS_TIM_COUNTING_DOWN(&htim5);
							sprintf(hello, "RD:%2d\0", dir);
							OLED_ShowString(10,30,hello);
							cnt1=__HAL_TIM_GET_COUNTER(&htim5);
							tick=HAL_GetTick();
							totaldist+=diff;
						}

					}

		    	 	    __HAL_TIM_SetCompare(&htim8, TIM_CHANNEL_4, 0);*/

		    	 	 	htim1.Instance->CCR4=93;

						totaldist=0;
						diff=0;
						cnt1=__HAL_TIM_GET_COUNTER(&htim5);
						HAL_GPIO_WritePin(GPIOB, DIN2_Pin, GPIO_PIN_SET);
						HAL_GPIO_WritePin(GPIOB, DIN1_Pin, GPIO_PIN_RESET);
						__HAL_TIM_SetCompare(&htim8, TIM_CHANNEL_4, 800);
						tick=HAL_GetTick();
						temp=tickbaseval*1;
						while(totaldist<temp)
						{
							if(HAL_GetTick()-tick>50L)
							{
								cnt2=__HAL_TIM_GET_COUNTER(&htim5);
								if(__HAL_TIM_IS_TIM_COUNTING_DOWN(&htim5))
								{
									if(cnt2<cnt1)
										diff=cnt1-cnt2;
									else
										diff=(65535-cnt2)+cnt1;
								}
								else
								{
									if(cnt2>cnt1)
										diff=cnt2-cnt1;
									else
										diff=(65535-cnt1)+cnt2;
								}

								sprintf(hello, "S:%5d\0", diff);
								OLED_ShowString(50,30,hello);
								dir = __HAL_TIM_IS_TIM_COUNTING_DOWN(&htim5);
								sprintf(hello, "RD:%2d\0", dir);
								OLED_ShowString(10,30,hello);
								cnt1=__HAL_TIM_GET_COUNTER(&htim5);
								tick=HAL_GetTick();
								totaldist+=diff;
							}
						}
/*
		     			HAL_GPIO_WritePin(GPIOB, DIN2_Pin, GPIO_PIN_SET);
		     			HAL_GPIO_WritePin(GPIOB, DIN1_Pin, GPIO_PIN_RESET);
		     			__HAL_TIM_SetCompare(&htim8, TIM_CHANNEL_4, 400);
		     			dist=(dist*32);
		     			osDelay(dist); //+3
*/

						while(stopwheel!=0)
							{
							__HAL_TIM_SetCompare(&htim8, TIM_CHANNEL_4, 0);
							osDelay(100);
							}

						__HAL_TIM_SetCompare(&htim8, TIM_CHANNEL_4, 0);

/*						osDelay(200);
						htim1.Instance->CCR4=93;
						osDelay(500);
						htim1.Instance->CCR4=58;
						osDelay(200);
						htim1.Instance->CCR4=76;*/

	  					flag=1;

		     			break;

		     case 12  :
/*		    	 	 	 HAL_GPIO_WritePin(GPIOB, DIN2_Pin, GPIO_PIN_SET);
		    	 		 HAL_GPIO_WritePin(GPIOB, DIN1_Pin, GPIO_PIN_RESET);
		    	 		 __HAL_TIM_SetCompare(&htim8, TIM_CHANNEL_4, pwmVal);
		    	 		 osDelay(val);*/
/*					totaldist=0;
					diff=0;
					cnt1=__HAL_TIM_GET_COUNTER(&htim5);
					htim1.Instance->CCR4=75;
					HAL_GPIO_WritePin(GPIOB, DIN2_Pin, GPIO_PIN_SET);
					HAL_GPIO_WritePin(GPIOB, DIN1_Pin, GPIO_PIN_RESET);
					__HAL_TIM_SetCompare(&htim8, TIM_CHANNEL_4, pwmVal);
					tick=HAL_GetTick();
					temp=tickbaseval*0.9;
					while(totaldist<temp)
					{
						if(HAL_GetTick()-tick>50L)
						{
							cnt2=__HAL_TIM_GET_COUNTER(&htim5);
							if(__HAL_TIM_IS_TIM_COUNTING_DOWN(&htim5))
							{
								if(cnt2<cnt1)
									diff=cnt1-cnt2;
								else
									diff=(65535-cnt2)+cnt1;
							}
							else
							{
								if(cnt2>cnt1)
									diff=cnt2-cnt1;
								else
									diff=(65535-cnt1)+cnt2;
							}

							sprintf(hello, "S:%5d\0", diff);
							OLED_ShowString(50,30,hello);
							dir = __HAL_TIM_IS_TIM_COUNTING_DOWN(&htim5);
							sprintf(hello, "RD:%2d\0", dir);
							OLED_ShowString(10,30,hello);
							cnt1=__HAL_TIM_GET_COUNTER(&htim5);
							tick=HAL_GetTick();
							totaldist+=diff;
						}

					}

		    	 		__HAL_TIM_SetCompare(&htim8, TIM_CHANNEL_4, 0);*/

		    	 	 	htim1.Instance->CCR4=58;

						totaldist=0;
						diff=0;
						cnt1=__HAL_TIM_GET_COUNTER(&htim5);
						HAL_GPIO_WritePin(GPIOB, DIN2_Pin, GPIO_PIN_SET);
						HAL_GPIO_WritePin(GPIOB, DIN1_Pin, GPIO_PIN_RESET);
						__HAL_TIM_SetCompare(&htim8, TIM_CHANNEL_4, 2500);
						tick=HAL_GetTick();
						temp=tickbaseval*4.8;//5.4 5.2 for scse lounge 5.3 corridor
						while(totaldist<temp)
						{
							if(HAL_GetTick()-tick>50L)
							{
								cnt2=__HAL_TIM_GET_COUNTER(&htim5);
								if(__HAL_TIM_IS_TIM_COUNTING_DOWN(&htim5))
								{
									if(cnt2<cnt1)
										diff=cnt1-cnt2;
									else
										diff=(65535-cnt2)+cnt1;
								}
								else
								{
									if(cnt2>cnt1)
										diff=cnt2-cnt1;
									else
										diff=(65535-cnt1)+cnt2;
								}

								sprintf(hello, "S:%5d\0", diff);
								OLED_ShowString(50,30,hello);
								dir = __HAL_TIM_IS_TIM_COUNTING_DOWN(&htim5);
								sprintf(hello, "RD:%2d\0", dir);
								OLED_ShowString(10,30,hello);
								cnt1=__HAL_TIM_GET_COUNTER(&htim5);
								tick=HAL_GetTick();
								totaldist+=diff;
							}

						}

						__HAL_TIM_SetCompare(&htim8, TIM_CHANNEL_4, 0);
//						osDelay(200);
//						htim1.Instance->CCR4=93;
//						osDelay(500);
//						htim1.Instance->CCR4=58;
//						osDelay(500);
//						htim1.Instance->CCR4=77;

						__HAL_TIM_SetCompare(&htim8, TIM_CHANNEL_4, 0);

		     			flag=1;
		     			break;
		     case 13 :
		    	 	 	move5=0;
		    	 	 	htim1.Instance->CCR4=58;

						totaldist=0;
						diff=0;
						cnt1=__HAL_TIM_GET_COUNTER(&htim5);
						HAL_GPIO_WritePin(GPIOB, DIN2_Pin, GPIO_PIN_SET);
						HAL_GPIO_WritePin(GPIOB, DIN1_Pin, GPIO_PIN_RESET);
						__HAL_TIM_SetCompare(&htim8, TIM_CHANNEL_4, 2500);
						tick=HAL_GetTick();
						temp=tickbaseval*4.9;//5.4 5.2 for scse lounge 5.3 corridor
						while(totaldist<temp)
						{
							if(HAL_GetTick()-tick>50L)
							{
								cnt2=__HAL_TIM_GET_COUNTER(&htim5);
								if(__HAL_TIM_IS_TIM_COUNTING_DOWN(&htim5))
								{
									if(cnt2<cnt1)
										diff=cnt1-cnt2;
									else
										diff=(65535-cnt2)+cnt1;
								}
								else
								{
									if(cnt2>cnt1)
										diff=cnt2-cnt1;
									else
										diff=(65535-cnt1)+cnt2;
								}

								sprintf(hello, "S:%5d\0", diff);
								OLED_ShowString(50,30,hello);
								dir = __HAL_TIM_IS_TIM_COUNTING_DOWN(&htim5);
								sprintf(hello, "RD:%2d\0", dir);
								OLED_ShowString(10,30,hello);
								cnt1=__HAL_TIM_GET_COUNTER(&htim5);
								tick=HAL_GetTick();
								totaldist+=diff;
							}

						}

						__HAL_TIM_SetCompare(&htim8, TIM_CHANNEL_4, 0);

						move5=1;

						totaldist=0;
						diff=0;
						cnt1=__HAL_TIM_GET_COUNTER(&htim5);
						htim1.Instance->CCR4=74;
						HAL_GPIO_WritePin(GPIOB, DIN2_Pin, GPIO_PIN_SET);
						HAL_GPIO_WritePin(GPIOB, DIN1_Pin, GPIO_PIN_RESET);
						__HAL_TIM_SetCompare(&htim8, TIM_CHANNEL_4, pwmVal);
						tick=HAL_GetTick();
						temp=tickbaseval*0.5;
						while(totaldist<temp)
						{
							if(HAL_GetTick()-tick>25L)
							{
								cnt2=__HAL_TIM_GET_COUNTER(&htim5);
								if(__HAL_TIM_IS_TIM_COUNTING_DOWN(&htim5))
								{
									if(cnt2<cnt1)
										diff=cnt1-cnt2;
									else
										diff=(65535-cnt2)+cnt1;
								}
								else
								{
									if(cnt2>cnt1)
										diff=cnt2-cnt1;
									else
										diff=(65535-cnt1)+cnt2;
								}

								sprintf(hello, "S:%5d\0", diff);
								OLED_ShowString(50,30,hello);
								dir = __HAL_TIM_IS_TIM_COUNTING_DOWN(&htim5);
								sprintf(hello, "RD:%2d\0", dir);
								OLED_ShowString(10,30,hello);
								cnt1=__HAL_TIM_GET_COUNTER(&htim5);
								tick=HAL_GetTick();
								totaldist+=diff;
							}

						}

							__HAL_TIM_SetCompare(&htim8, TIM_CHANNEL_4, 0);

		     			flag=1;
		     			break;
		     case 20 :

					totaldist=0;
					diff=0;
					cnt1=__HAL_TIM_GET_COUNTER(&htim5);
					htim1.Instance->CCR4=74;
		  		  	HAL_GPIO_WritePin(GPIOB, DIN2_Pin, GPIO_PIN_RESET);
		  		  	HAL_GPIO_WritePin(GPIOB, DIN1_Pin, GPIO_PIN_SET);
					__HAL_TIM_SetCompare(&htim8, TIM_CHANNEL_4, pwmVal);
					tick=HAL_GetTick();
					temp=tickbaseval*dist;
					while(totaldist<temp)
					{
						if(HAL_GetTick()-tick>50L)
						{
							cnt2=__HAL_TIM_GET_COUNTER(&htim5);
							if(__HAL_TIM_IS_TIM_COUNTING_DOWN(&htim5))
							{
								if(cnt2<cnt1)
									diff=cnt1-cnt2;
								else
									diff=(65535-cnt2)+cnt1;
							}
							else
							{
								if(cnt2>cnt1)
									diff=cnt2-cnt1;
								else
									diff=(65535-cnt1)+cnt2;
							}

							sprintf(hello, "S:%5d\0", diff);
							OLED_ShowString(50,30,hello);
							dir = __HAL_TIM_IS_TIM_COUNTING_DOWN(&htim5);
							sprintf(hello, "RD:%2d\0", dir);
							OLED_ShowString(10,30,hello);
							cnt1=__HAL_TIM_GET_COUNTER(&htim5);
							tick=HAL_GetTick();
							totaldist+=diff;
						}

					}
					__HAL_TIM_SetCompare(&htim8, TIM_CHANNEL_4, 0);
/*					osDelay(200);
					htim1.Instance->CCR4=85;
					osDelay(500);
					htim1.Instance->CCR4=60;
					osDelay(500);
					htim1.Instance->CCR4=77;*/
					if(dist==1 || dist==2)
						{
						osDelay(1000);
						}
					flag=1;
					break;

/*		    	 	 	htim1.Instance->CCR4=75;
			  		  	HAL_GPIO_WritePin(GPIOB, DIN2_Pin, GPIO_PIN_RESET);
			  		  	HAL_GPIO_WritePin(GPIOB, DIN1_Pin, GPIO_PIN_SET);
			  	  		__HAL_TIM_SetCompare(&htim8, TIM_CHANNEL_4, pwmVal);
			  	  		dist=dist*720;
			  	  		osDelay(dist);
			  	  		flag=1;
			  	  		__HAL_TIM_SetCompare(&htim8, TIM_CHANNEL_4, 0);
			  	  		osDelay(200);
			  	  		if(dist==720)
			  	  		{
			  	  			osDelay(1000);
			  	  		}*/

		     case 26  :

		    	 	 	htim1.Instance->CCR4=58;

						totaldist=0;
						diff=0;
						cnt1=__HAL_TIM_GET_COUNTER(&htim5);
						HAL_GPIO_WritePin(GPIOB, DIN2_Pin, GPIO_PIN_RESET);
						HAL_GPIO_WritePin(GPIOB, DIN1_Pin, GPIO_PIN_SET);
						__HAL_TIM_SetCompare(&htim8, TIM_CHANNEL_4, 2500);
						tick=HAL_GetTick();
						temp=tickbaseval*2.2;
						while(totaldist<temp)
						{
							if(HAL_GetTick()-tick>50L)
							{
								cnt2=__HAL_TIM_GET_COUNTER(&htim5);
								if(__HAL_TIM_IS_TIM_COUNTING_DOWN(&htim5))
								{
									if(cnt2<cnt1)
										diff=cnt1-cnt2;
									else
										diff=(65535-cnt2)+cnt1;
								}
								else
								{
									if(cnt2>cnt1)
										diff=cnt2-cnt1;
									else
										diff=(65535-cnt1)+cnt2;
								}

								sprintf(hello, "S:%5d\0", diff);
								OLED_ShowString(50,30,hello);
								dir = __HAL_TIM_IS_TIM_COUNTING_DOWN(&htim5);
								sprintf(hello, "RD:%2d\0", dir);
								OLED_ShowString(10,30,hello);
								cnt1=__HAL_TIM_GET_COUNTER(&htim5);
								tick=HAL_GetTick();
								totaldist+=diff;
							}

						}

						__HAL_TIM_SetCompare(&htim8, TIM_CHANNEL_4, 0);

		     			flag=1;
		     			break;

		     case 21 :

		    	 	 	htim1.Instance->CCR4=93;
		    	 	 	osDelay(100);
			  		  	HAL_GPIO_WritePin(GPIOB, DIN2_Pin, GPIO_PIN_RESET);
			  		  	HAL_GPIO_WritePin(GPIOB, DIN1_Pin, GPIO_PIN_SET);
			  	  		__HAL_TIM_SetCompare(&htim8, TIM_CHANNEL_4, 400);
			  	  		osDelay(dist*43);
			  	  		__HAL_TIM_SetCompare(&htim8, TIM_CHANNEL_4, 0);
			  	  		htim1.Instance->CCR4=74;
			  	  		flag=1;
			  	  		break;

		     case 22 :

		    	 	 	htim1.Instance->CCR4=58;
		    	 	 	osDelay(100);
			  		  	HAL_GPIO_WritePin(GPIOB, DIN2_Pin, GPIO_PIN_RESET);
			  		  	HAL_GPIO_WritePin(GPIOB, DIN1_Pin, GPIO_PIN_SET);
			  	  		__HAL_TIM_SetCompare(&htim8, TIM_CHANNEL_4, 1500);
			  	  		osDelay(dist*38);
			  	  		htim1.Instance->CCR4=85;
			  	  	    __HAL_TIM_SetCompare(&htim8, TIM_CHANNEL_4, 0);
			  	  		osDelay(100);
			  	  		flag=1;
			  	  		break;

			  case 0  :

		    	 	 	__HAL_TIM_SetCompare(&htim8, TIM_CHANNEL_4, 0);
		    	 	 	if(flag==1)
		    	 	 	{
		    	 	 		htim1.Instance->CCR4=77;
		    	 	 		sprintf(home,"%s\0","READY");
		    	 	 		HAL_UART_Transmit(&huart3, (uint8_t *)home,5,0xFFFF);
		    	 	 		flag=0;
		    	 	 	}

		    	 	 	break;

		     default :
		    	 	 	  htim1.Instance->CCR4=76;
		    	 	 	__HAL_TIM_SetCompare(&htim8, TIM_CHANNEL_4, 0);
		    	 	 	break;
		  }

	  }
  /* USER CODE END rightmotor */
}

void leftmotor(void *argument)
{
  /* USER CODE BEGIN leftmotor */
  /* Infinite loop */
	uint16_t pwmVal=3700;
	HAL_TIM_PWM_Start(&htim8,TIM_CHANNEL_3);
	uint32_t val=0;
	val=1.25*750;

	HAL_TIM_Encoder_Start(&htim4,TIM_CHANNEL_ALL);
	int cnt3,cnt4,diff;
	int backdistance;
	uint32_t tick;
	uint16_t dir;
	uint32_t tickbaseval=520;
	uint32_t totaldist=0;
	uint32_t dist=0;
	uint32_t temp;
	uint8_t hello[20];

	int x;
		for(;;)
		{
			  x=atoi(value);
			  dist = (uint32_t)(x%1000); //Get last 2 Digit
			  x/=1000;
			  switch(x) {
				case 30	:

									totaldist=0;
									diff=0;
									cnt3=__HAL_TIM_GET_COUNTER(&htim4);

							 	 	HAL_GPIO_WritePin(GPIOE, CIN1_Pin, GPIO_PIN_SET);
							  		HAL_GPIO_WritePin(CIN2_GPIO_Port, CIN2_Pin, GPIO_PIN_RESET);
							  		__HAL_TIM_SetCompare(&htim8, TIM_CHANNEL_3, pwmVal);
									tick=HAL_GetTick();
									temp=sensordist/10;
									backdistance=temp;
									temp=tickbaseval*(temp-5);
									if(backdistance>=8)
									{
										while(totaldist<temp)
										{
//											if(sensordist<=37)
//											{
//												break;
//											}
										  if(HAL_GetTick()-tick>25L){
											  cnt4=__HAL_TIM_GET_COUNTER(&htim4);
											  if(__HAL_TIM_IS_TIM_COUNTING_DOWN(&htim4))
											  {
												  if(cnt4<cnt3)
													diff=cnt3-cnt4;
												  else
													diff=(65535-cnt4)+cnt3;
											  }
											  else
											  {
													if(cnt4>cnt3)
														diff=cnt4-cnt3;
													else
														diff=(65535-cnt3)+cnt4;
											  }
												sprintf(hello, "S:%5d\0", diff);
												OLED_ShowString(50,20,hello);
												dir = __HAL_TIM_IS_TIM_COUNTING_DOWN(&htim4);
												sprintf(hello, "LD:%2d\0", dir);
												OLED_ShowString(10,20,hello);
												cnt3=__HAL_TIM_GET_COUNTER(&htim4);
												tick=HAL_GetTick();
												totaldist+=diff;
											}
										}
									}
									else
									{
										while(totaldist<temp)
										{
											if(sensordist<=37)
											{
												break;
											}
										  if(HAL_GetTick()-tick>25L){
											  cnt4=__HAL_TIM_GET_COUNTER(&htim4);
											  if(__HAL_TIM_IS_TIM_COUNTING_DOWN(&htim4))
											  {
												  if(cnt4<cnt3)
													diff=cnt3-cnt4;
												  else
													diff=(65535-cnt4)+cnt3;
											  }
											  else
											  {
													if(cnt4>cnt3)
														diff=cnt4-cnt3;
													else
														diff=(65535-cnt3)+cnt4;
											  }
												sprintf(hello, "S:%5d\0", diff);
												OLED_ShowString(50,20,hello);
												dir = __HAL_TIM_IS_TIM_COUNTING_DOWN(&htim4);
												sprintf(hello, "LD:%2d\0", dir);
												OLED_ShowString(10,20,hello);
												cnt3=__HAL_TIM_GET_COUNTER(&htim4);
												tick=HAL_GetTick();
												totaldist+=diff;
											}
										}

									}
									__HAL_TIM_SetCompare(&htim8, TIM_CHANNEL_3, 0);

			 	 	HAL_GPIO_WritePin(GPIOE, CIN1_Pin, GPIO_PIN_SET);
			  		HAL_GPIO_WritePin(CIN2_GPIO_Port, CIN2_Pin, GPIO_PIN_RESET);
			  		for(int i=0; i<3;i++)
			  		{
						while(sensordist>=37)
						{
					  		__HAL_TIM_SetCompare(&htim8, TIM_CHANNEL_3, pwmVal);
					  		osDelay(50);
						}

			  		}
			  		__HAL_TIM_SetCompare(&htim8, TIM_CHANNEL_3, 0);
						break;
				case 40	:

					totaldist=0;
					diff=0;
					cnt3=__HAL_TIM_GET_COUNTER(&htim4);

					HAL_GPIO_WritePin(GPIOE, CIN1_Pin, GPIO_PIN_SET);
					HAL_GPIO_WritePin(CIN2_GPIO_Port, CIN2_Pin, GPIO_PIN_RESET);
					__HAL_TIM_SetCompare(&htim8, TIM_CHANNEL_3, pwmVal);
					tick=HAL_GetTick();
					temp=backdistance-2;
					temp=tickbaseval*(temp-5);
					if(backdistance>=8)
					{
						while(totaldist<temp)
						{
//							if(sensordist<=25)
//							{
//								break;
//							}
						  if(HAL_GetTick()-tick>25L){
							  cnt4=__HAL_TIM_GET_COUNTER(&htim4);
							  if(__HAL_TIM_IS_TIM_COUNTING_DOWN(&htim4))
							  {
								  if(cnt4<cnt3)
									diff=cnt3-cnt4;
								  else
									diff=(65535-cnt4)+cnt3;
							  }
							  else
							  {
									if(cnt4>cnt3)
										diff=cnt4-cnt3;
									else
										diff=(65535-cnt3)+cnt4;
							  }
								sprintf(hello, "S:%5d\0", diff);
								OLED_ShowString(50,20,hello);
								dir = __HAL_TIM_IS_TIM_COUNTING_DOWN(&htim4);
								sprintf(hello, "LD:%2d\0", dir);
								OLED_ShowString(10,20,hello);
								cnt3=__HAL_TIM_GET_COUNTER(&htim4);
								tick=HAL_GetTick();
								totaldist+=diff;
							}
						}
					}
					__HAL_TIM_SetCompare(&htim8, TIM_CHANNEL_3, 0);

			 	 	HAL_GPIO_WritePin(GPIOE, CIN1_Pin, GPIO_PIN_SET);
			  		HAL_GPIO_WritePin(CIN2_GPIO_Port, CIN2_Pin, GPIO_PIN_RESET);
			  		for(int i=0; i<3;i++)
			  		{
						while(sensordist>=25)
						{
					  		__HAL_TIM_SetCompare(&htim8, TIM_CHANNEL_3, pwmVal);
					  		osDelay(50);
						}

			  		}
			  		__HAL_TIM_SetCompare(&htim8, TIM_CHANNEL_3, 0);
						break;
				case 50	:

									totaldist=0;
									diff=0;
									cnt3=__HAL_TIM_GET_COUNTER(&htim4);

							 	 	HAL_GPIO_WritePin(GPIOE, CIN1_Pin, GPIO_PIN_SET);
							  		HAL_GPIO_WritePin(CIN2_GPIO_Port, CIN2_Pin, GPIO_PIN_RESET);
							  		__HAL_TIM_SetCompare(&htim8, TIM_CHANNEL_3, 6000);
									tick=HAL_GetTick();
									temp=sensordist/10;
									backdistance=temp;
									temp=tickbaseval*(temp-5);
									if(backdistance>=8)
									{
										while(totaldist<temp)
										{

										  if(HAL_GetTick()-tick>25L){
											  cnt4=__HAL_TIM_GET_COUNTER(&htim4);
											  if(__HAL_TIM_IS_TIM_COUNTING_DOWN(&htim4))
											  {
												  if(cnt4<cnt3)
													diff=cnt3-cnt4;
												  else
													diff=(65535-cnt4)+cnt3;
											  }
											  else
											  {
													if(cnt4>cnt3)
														diff=cnt4-cnt3;
													else
														diff=(65535-cnt3)+cnt4;
											  }
												sprintf(hello, "S:%5d\0", diff);
												OLED_ShowString(50,20,hello);
												dir = __HAL_TIM_IS_TIM_COUNTING_DOWN(&htim4);
												sprintf(hello, "LD:%2d\0", dir);
												OLED_ShowString(10,20,hello);
												cnt3=__HAL_TIM_GET_COUNTER(&htim4);
												tick=HAL_GetTick();
												totaldist+=diff;
											}
										}
									}
									else
									{
										while(totaldist<temp)
										{
											if(sensordist<=37)
											{
												break;
											}
										  if(HAL_GetTick()-tick>25L){
											  cnt4=__HAL_TIM_GET_COUNTER(&htim4);
											  if(__HAL_TIM_IS_TIM_COUNTING_DOWN(&htim4))
											  {
												  if(cnt4<cnt3)
													diff=cnt3-cnt4;
												  else
													diff=(65535-cnt4)+cnt3;
											  }
											  else
											  {
													if(cnt4>cnt3)
														diff=cnt4-cnt3;
													else
														diff=(65535-cnt3)+cnt4;
											  }
												sprintf(hello, "S:%5d\0", diff);
												OLED_ShowString(50,20,hello);
												dir = __HAL_TIM_IS_TIM_COUNTING_DOWN(&htim4);
												sprintf(hello, "LD:%2d\0", dir);
												OLED_ShowString(10,20,hello);
												cnt3=__HAL_TIM_GET_COUNTER(&htim4);
												tick=HAL_GetTick();
												totaldist+=diff;
											}
										}

									}
									__HAL_TIM_SetCompare(&htim8, TIM_CHANNEL_3, 0);

			 	 	HAL_GPIO_WritePin(GPIOE, CIN1_Pin, GPIO_PIN_SET);
			  		HAL_GPIO_WritePin(CIN2_GPIO_Port, CIN2_Pin, GPIO_PIN_RESET);
			  		for(int i=0; i<3;i++)
			  		{
						while(sensordist>=37)
						{
					  		__HAL_TIM_SetCompare(&htim8, TIM_CHANNEL_3, 6000);
					  		osDelay(50);
						}

			  		}
			  		__HAL_TIM_SetCompare(&htim8, TIM_CHANNEL_3, 0);
						break;
				case 60	:

					totaldist=0;
					diff=0;
					cnt3=__HAL_TIM_GET_COUNTER(&htim4);

					HAL_GPIO_WritePin(GPIOE, CIN1_Pin, GPIO_PIN_SET);
					HAL_GPIO_WritePin(CIN2_GPIO_Port, CIN2_Pin, GPIO_PIN_RESET);
					__HAL_TIM_SetCompare(&htim8, TIM_CHANNEL_3, 6000);
					tick=HAL_GetTick();
					temp=backdistance-2;
					temp=tickbaseval*(temp-5);
					if(backdistance>=8)
					{
						while(totaldist<temp)
						{

						  if(HAL_GetTick()-tick>25L){
							  cnt4=__HAL_TIM_GET_COUNTER(&htim4);
							  if(__HAL_TIM_IS_TIM_COUNTING_DOWN(&htim4))
							  {
								  if(cnt4<cnt3)
									diff=cnt3-cnt4;
								  else
									diff=(65535-cnt4)+cnt3;
							  }
							  else
							  {
									if(cnt4>cnt3)
										diff=cnt4-cnt3;
									else
										diff=(65535-cnt3)+cnt4;
							  }
								sprintf(hello, "S:%5d\0", diff);
								OLED_ShowString(50,20,hello);
								dir = __HAL_TIM_IS_TIM_COUNTING_DOWN(&htim4);
								sprintf(hello, "LD:%2d\0", dir);
								OLED_ShowString(10,20,hello);
								cnt3=__HAL_TIM_GET_COUNTER(&htim4);
								tick=HAL_GetTick();
								totaldist+=diff;
							}
						}
					}
					__HAL_TIM_SetCompare(&htim8, TIM_CHANNEL_3, 0);

			 	 	HAL_GPIO_WritePin(GPIOE, CIN1_Pin, GPIO_PIN_SET);
			  		HAL_GPIO_WritePin(CIN2_GPIO_Port, CIN2_Pin, GPIO_PIN_RESET);
			  		for(int i=0; i<3;i++)
			  		{
						while(sensordist>=25)
						{
					  		__HAL_TIM_SetCompare(&htim8, TIM_CHANNEL_3, 6000);
					  		osDelay(50);
						}

			  		}
			  		__HAL_TIM_SetCompare(&htim8, TIM_CHANNEL_3, 0);
						break;
				case 18: //Turn Left 180
					totaldist=0;
					diff=0;
					cnt3=__HAL_TIM_GET_COUNTER(&htim4);

					HAL_GPIO_WritePin(GPIOE, CIN1_Pin, GPIO_PIN_SET);
					HAL_GPIO_WritePin(CIN2_GPIO_Port, CIN2_Pin, GPIO_PIN_RESET);
					__HAL_TIM_SetCompare(&htim8, TIM_CHANNEL_3, 1000);
					tick=HAL_GetTick();
					temp=tickbaseval*1.5;
					while(totaldist<temp)
					{
					  if(HAL_GetTick()-tick>50L){
						  cnt4=__HAL_TIM_GET_COUNTER(&htim4);
						  if(__HAL_TIM_IS_TIM_COUNTING_DOWN(&htim4))
						  {
							  if(cnt4<cnt3)
								diff=cnt3-cnt4;
							  else
								diff=(65535-cnt4)+cnt3;
						  }
						  else
						  {
								if(cnt4>cnt3)
									diff=cnt4-cnt3;
								else
									diff=(65535-cnt3)+cnt4;
						  }
							sprintf(hello, "S:%5d\0", diff);
							OLED_ShowString(50,20,hello);
							dir = __HAL_TIM_IS_TIM_COUNTING_DOWN(&htim4);
							sprintf(hello, "LD:%2d\0", dir);
							OLED_ShowString(10,20,hello);
							cnt3=__HAL_TIM_GET_COUNTER(&htim4);
							tick=HAL_GetTick();
							totaldist+=diff;
						}
					}
					__HAL_TIM_SetCompare(&htim8, TIM_CHANNEL_3, 0);
					break;
	  	  	  	  case 10 :
/*	    		 	 	HAL_GPIO_WritePin(GPIOE, CIN1_Pin, GPIO_PIN_SET);
	    		  		 HAL_GPIO_WritePin(CIN2_GPIO_Port, CIN2_Pin, GPIO_PIN_RESET);
	    		  		 __HAL_TIM_SetCompare(&htim8, TIM_CHANNEL_3, pwmVal);
	    		  		 dist=dist*700;
	    		  		 osDelay(dist);
	    		  		 __HAL_TIM_SetCompare(&htim8, TIM_CHANNEL_3, 0);
	    		  		 osDelay(200);
	    		  		if(dist==700)
	    		  		{
	    		  			osDelay(1000);
	    		  		}*/

	  	  	  	totaldist=0;
				diff=0;
				cnt3=__HAL_TIM_GET_COUNTER(&htim4);

		 	 	HAL_GPIO_WritePin(GPIOE, CIN1_Pin, GPIO_PIN_SET);
		  		HAL_GPIO_WritePin(CIN2_GPIO_Port, CIN2_Pin, GPIO_PIN_RESET);
		  		__HAL_TIM_SetCompare(&htim8, TIM_CHANNEL_3, pwmVal);
				tick=HAL_GetTick();
				temp=tickbaseval*dist*0.85;
				while(totaldist<temp)
				{
	  		  	  if(HAL_GetTick()-tick>25L){
	  		  		  cnt4=__HAL_TIM_GET_COUNTER(&htim4);
	  		  		  if(__HAL_TIM_IS_TIM_COUNTING_DOWN(&htim4))
	  		  		  {
	  		  			  if(cnt4<cnt3)
							diff=cnt3-cnt4;
	  		  			  else
							diff=(65535-cnt4)+cnt3;
	  		  		  }
	  		  		  else
	  		  		  {
							if(cnt4>cnt3)
								diff=cnt4-cnt3;
							else
								diff=(65535-cnt3)+cnt4;
	  		  		  }
						sprintf(hello, "S:%5d\0", diff);
						OLED_ShowString(50,20,hello);
						dir = __HAL_TIM_IS_TIM_COUNTING_DOWN(&htim4);
						sprintf(hello, "LD:%2d\0", dir);
						OLED_ShowString(10,20,hello);
						cnt3=__HAL_TIM_GET_COUNTER(&htim4);
						tick=HAL_GetTick();
						totaldist+=diff;
	  		  		}
				}
				__HAL_TIM_SetCompare(&htim8, TIM_CHANNEL_3, 0);
				if(dist==1 || dist==2)
				{
					osDelay(1000);
				}
/*				osDelay(200);
				osDelay(1000);*/

	    		  		 break;
	  	  	  	case 11 :
/*	  	  	  			 HAL_GPIO_WritePin(GPIOE, CIN1_Pin, GPIO_PIN_SET);
	  	  	  			 HAL_GPIO_WritePin(CIN2_GPIO_Port, CIN2_Pin, GPIO_PIN_RESET);
	  	  	  			 __HAL_TIM_SetCompare(&htim8, TIM_CHANNEL_3, pwmVal);
	  	  	  			 osDelay(val);*/

/*	  	  	  		totaldist=0;
					diff=0;
					cnt3=__HAL_TIM_GET_COUNTER(&htim4);

			 	 	HAL_GPIO_WritePin(GPIOE, CIN1_Pin, GPIO_PIN_SET);
			  		HAL_GPIO_WritePin(CIN2_GPIO_Port, CIN2_Pin, GPIO_PIN_RESET);
			  		__HAL_TIM_SetCompare(&htim8, TIM_CHANNEL_3, pwmVal);
					tick=HAL_GetTick();
					temp=tickbaseval*0.8;
					while(totaldist<temp)
					{
		  		  	  if(HAL_GetTick()-tick>50L){
		  		  		  cnt4=__HAL_TIM_GET_COUNTER(&htim4);
		  		  		  if(__HAL_TIM_IS_TIM_COUNTING_DOWN(&htim4))
		  		  		  {
		  		  			  if(cnt4<cnt3)
								diff=cnt3-cnt4;
		  		  			  else
								diff=(65535-cnt4)+cnt3;
		  		  		  }
		  		  		  else
		  		  		  {
								if(cnt4>cnt3)
									diff=cnt4-cnt3;
								else
									diff=(65535-cnt3)+cnt4;
		  		  		  }
							sprintf(hello, "S:%5d\0", diff);
							OLED_ShowString(50,20,hello);
							dir = __HAL_TIM_IS_TIM_COUNTING_DOWN(&htim4);
							sprintf(hello, "LD:%2d\0", dir);
							OLED_ShowString(10,20,hello);
							cnt3=__HAL_TIM_GET_COUNTER(&htim4);
							tick=HAL_GetTick();
							totaldist+=diff;
		  		  		}
					}

	  	  	  			 __HAL_TIM_SetCompare(&htim8, TIM_CHANNEL_3, 0);*/

	  		  	  	  	totaldist=0;
	  					diff=0;
	  					cnt3=__HAL_TIM_GET_COUNTER(&htim4);

	  			 	 	HAL_GPIO_WritePin(GPIOE, CIN1_Pin, GPIO_PIN_SET);
	  			  		HAL_GPIO_WritePin(CIN2_GPIO_Port, CIN2_Pin, GPIO_PIN_RESET);
	  			  		__HAL_TIM_SetCompare(&htim8, TIM_CHANNEL_3, 2500);
	  					tick=HAL_GetTick();
	  					temp=tickbaseval*5.3;//6 for scse lounge 6.1 for outside scse

	  					while(totaldist<temp)
	  					{
	  		  		  	  if(HAL_GetTick()-tick>50L){
	  		  		  		  cnt4=__HAL_TIM_GET_COUNTER(&htim4);
	  		  		  		  if(__HAL_TIM_IS_TIM_COUNTING_DOWN(&htim4))
	  		  		  		  {
	  		  		  			  if(cnt4<cnt3)
	  								diff=cnt3-cnt4;
	  		  		  			  else
	  								diff=(65535-cnt4)+cnt3;
	  		  		  		  }
	  		  		  		  else
	  		  		  		  {
	  								if(cnt4>cnt3)
	  									diff=cnt4-cnt3;
	  								else
	  									diff=(65535-cnt3)+cnt4;
	  		  		  		  }
	  							sprintf(hello, "S:%5d\0", diff);
	  							OLED_ShowString(50,20,hello);
	  							dir = __HAL_TIM_IS_TIM_COUNTING_DOWN(&htim4);
	  							sprintf(hello, "LD:%2d\0", dir);
	  							OLED_ShowString(10,20,hello);
	  							cnt3=__HAL_TIM_GET_COUNTER(&htim4);
	  							tick=HAL_GetTick();
	  							totaldist+=diff;
	  		  		  		}
	  					}

/*	    		 	 	 HAL_GPIO_WritePin(GPIOE, CIN1_Pin, GPIO_PIN_SET);
	    		  		 HAL_GPIO_WritePin(CIN2_GPIO_Port, CIN2_Pin, GPIO_PIN_RESET);
	    		  		 __HAL_TIM_SetCompare(&htim8, TIM_CHANNEL_3, 1500);
	    		  		 dist=dist*33;
	    		  		 osDelay(dist);*/
	  					__HAL_TIM_SetCompare(&htim8, TIM_CHANNEL_3, 0);

	  					stopwheel=0;

//	  					osDelay(200);
//	  					osDelay(1000);

	    		  		 break;
	  	  	  	case 12 :
/*	  	  	  			HAL_GPIO_WritePin(GPIOE, CIN1_Pin, GPIO_PIN_SET);
	  	  	  			HAL_GPIO_WritePin(CIN2_GPIO_Port, CIN2_Pin, GPIO_PIN_RESET);
	  	  	  			__HAL_TIM_SetCompare(&htim8, TIM_CHANNEL_3, pwmVal);
	  	  	  			osDelay(val);*/

/*		  	  	  	totaldist=0;
					diff=0;
					cnt3=__HAL_TIM_GET_COUNTER(&htim4);

			 	 	HAL_GPIO_WritePin(GPIOE, CIN1_Pin, GPIO_PIN_SET);
			  		HAL_GPIO_WritePin(CIN2_GPIO_Port, CIN2_Pin, GPIO_PIN_RESET);
			  		__HAL_TIM_SetCompare(&htim8, TIM_CHANNEL_3, pwmVal);
					tick=HAL_GetTick();
					temp=tickbaseval*0.9;
					while(totaldist<temp)
					{
		  		  	  if(HAL_GetTick()-tick>50L){
		  		  		  cnt4=__HAL_TIM_GET_COUNTER(&htim4);
		  		  		  if(__HAL_TIM_IS_TIM_COUNTING_DOWN(&htim4))
		  		  		  {
		  		  			  if(cnt4<cnt3)
								diff=cnt3-cnt4;
		  		  			  else
								diff=(65535-cnt4)+cnt3;
		  		  		  }
		  		  		  else
		  		  		  {
								if(cnt4>cnt3)
									diff=cnt4-cnt3;
								else
									diff=(65535-cnt3)+cnt4;
		  		  		  }
							sprintf(hello, "S:%5d\0", diff);
							OLED_ShowString(50,20,hello);
							dir = __HAL_TIM_IS_TIM_COUNTING_DOWN(&htim4);
							sprintf(hello, "LD:%2d\0", dir);
							OLED_ShowString(10,20,hello);
							cnt3=__HAL_TIM_GET_COUNTER(&htim4);
							tick=HAL_GetTick();
							totaldist+=diff;
		  		  		}
					}

	  	  	  			__HAL_TIM_SetCompare(&htim8, TIM_CHANNEL_3, 0);*/

			  	  	  	totaldist=0;
						diff=0;
						cnt3=__HAL_TIM_GET_COUNTER(&htim4);

				 	 	HAL_GPIO_WritePin(GPIOE, CIN1_Pin, GPIO_PIN_SET);
				  		HAL_GPIO_WritePin(CIN2_GPIO_Port, CIN2_Pin, GPIO_PIN_RESET);
				  		__HAL_TIM_SetCompare(&htim8, TIM_CHANNEL_3, 800);
						tick=HAL_GetTick();
						temp=tickbaseval*1;
						while(totaldist<temp)
						{
			  		  	  if(HAL_GetTick()-tick>50L){
			  		  		  cnt4=__HAL_TIM_GET_COUNTER(&htim4);
			  		  		  if(__HAL_TIM_IS_TIM_COUNTING_DOWN(&htim4))
			  		  		  {
			  		  			  if(cnt4<cnt3)
									diff=cnt3-cnt4;
			  		  			  else
									diff=(65535-cnt4)+cnt3;
			  		  		  }
			  		  		  else
			  		  		  {
									if(cnt4>cnt3)
										diff=cnt4-cnt3;
									else
										diff=(65535-cnt3)+cnt4;
			  		  		  }
								sprintf(hello, "S:%5d\0", diff);
								OLED_ShowString(50,20,hello);
								dir = __HAL_TIM_IS_TIM_COUNTING_DOWN(&htim4);
								sprintf(hello, "LD:%2d\0", dir);
								OLED_ShowString(10,20,hello);
								cnt3=__HAL_TIM_GET_COUNTER(&htim4);
								tick=HAL_GetTick();
								totaldist+=diff;
			  		  		}
						}

	  					__HAL_TIM_SetCompare(&htim8, TIM_CHANNEL_3, 0);
/*	    		 	 	 HAL_GPIO_WritePin(GPIOE, CIN1_Pin, GPIO_PIN_SET);
	    		  		 HAL_GPIO_WritePin(CIN2_GPIO_Port, CIN2_Pin, GPIO_PIN_RESET);
	    		  		 __HAL_TIM_SetCompare(&htim8, TIM_CHANNEL_3, 400);
	    		  		 dist=dist*31;
	    		  		 osDelay(dist);*/
//						osDelay(200);
//						osDelay(1000);
	    		  		 break;
	  	  	  	case 13 :

			  	  	  	totaldist=0;
						diff=0;
						cnt3=__HAL_TIM_GET_COUNTER(&htim4);

				 	 	HAL_GPIO_WritePin(GPIOE, CIN1_Pin, GPIO_PIN_SET);
				  		HAL_GPIO_WritePin(CIN2_GPIO_Port, CIN2_Pin, GPIO_PIN_RESET);
				  		__HAL_TIM_SetCompare(&htim8, TIM_CHANNEL_3, 800);
						tick=HAL_GetTick();
						temp=tickbaseval*1;
						while(totaldist<temp)
						{
			  		  	  if(HAL_GetTick()-tick>50L){
			  		  		  cnt4=__HAL_TIM_GET_COUNTER(&htim4);
			  		  		  if(__HAL_TIM_IS_TIM_COUNTING_DOWN(&htim4))
			  		  		  {
			  		  			  if(cnt4<cnt3)
									diff=cnt3-cnt4;
			  		  			  else
									diff=(65535-cnt4)+cnt3;
			  		  		  }
			  		  		  else
			  		  		  {
									if(cnt4>cnt3)
										diff=cnt4-cnt3;
									else
										diff=(65535-cnt3)+cnt4;
			  		  		  }
								sprintf(hello, "S:%5d\0", diff);
								OLED_ShowString(50,20,hello);
								dir = __HAL_TIM_IS_TIM_COUNTING_DOWN(&htim4);
								sprintf(hello, "LD:%2d\0", dir);
								OLED_ShowString(10,20,hello);
								cnt3=__HAL_TIM_GET_COUNTER(&htim4);
								tick=HAL_GetTick();
								totaldist+=diff;
			  		  		}
						}

	  					__HAL_TIM_SetCompare(&htim8, TIM_CHANNEL_3, 0);
	  					while(move5!=1)
	  					{
	  						osDelay(10);
	  					}
	  					totaldist=0;
						diff=0;
						cnt3=__HAL_TIM_GET_COUNTER(&htim4);

						HAL_GPIO_WritePin(GPIOE, CIN1_Pin, GPIO_PIN_SET);
						HAL_GPIO_WritePin(CIN2_GPIO_Port, CIN2_Pin, GPIO_PIN_RESET);
						__HAL_TIM_SetCompare(&htim8, TIM_CHANNEL_3, pwmVal);
						tick=HAL_GetTick();
						temp=tickbaseval*0.5;
						while(totaldist<temp)
						{
						  if(HAL_GetTick()-tick>25L){
							  cnt4=__HAL_TIM_GET_COUNTER(&htim4);
							  if(__HAL_TIM_IS_TIM_COUNTING_DOWN(&htim4))
							  {
								  if(cnt4<cnt3)
									diff=cnt3-cnt4;
								  else
									diff=(65535-cnt4)+cnt3;
							  }
							  else
							  {
									if(cnt4>cnt3)
										diff=cnt4-cnt3;
									else
										diff=(65535-cnt3)+cnt4;
							  }
								sprintf(hello, "S:%5d\0", diff);
								OLED_ShowString(50,20,hello);
								dir = __HAL_TIM_IS_TIM_COUNTING_DOWN(&htim4);
								sprintf(hello, "LD:%2d\0", dir);
								OLED_ShowString(10,20,hello);
								cnt3=__HAL_TIM_GET_COUNTER(&htim4);
								tick=HAL_GetTick();
								totaldist+=diff;
							}
						}

							__HAL_TIM_SetCompare(&htim8, TIM_CHANNEL_3, 0);

	    		  		 break;
	  	  	  	case 20  :
/*		  		  	  	  HAL_GPIO_WritePin(GPIOE, CIN1_Pin, GPIO_PIN_RESET);
		  		  	  	  HAL_GPIO_WritePin(CIN2_GPIO_Port, CIN2_Pin, GPIO_PIN_SET);
		  		  	  	  __HAL_TIM_SetCompare(&htim8, TIM_CHANNEL_3, pwmVal);
		  		  	  	  dist=dist*720;
		  		  	  	  osDelay(dist);
		  		  	      __HAL_TIM_SetCompare(&htim8, TIM_CHANNEL_3, 0);
		  		  	  	  osDelay(200);
		  		  	  	  if(dist==720)
		  		  	  	  {
		  		  	  		  osDelay(1000);
		  		  	  	  }*/

		  	  	  	totaldist=0;
					diff=0;
					cnt3=__HAL_TIM_GET_COUNTER(&htim4);

			 	 	HAL_GPIO_WritePin(GPIOE, CIN1_Pin, GPIO_PIN_RESET);
			  		HAL_GPIO_WritePin(CIN2_GPIO_Port, CIN2_Pin, GPIO_PIN_SET);
			  		__HAL_TIM_SetCompare(&htim8, TIM_CHANNEL_3, pwmVal);
					tick=HAL_GetTick();
					temp=tickbaseval*dist;
					while(totaldist<temp)
					{
		  		  	  if(HAL_GetTick()-tick>50L){
		  		  		  cnt4=__HAL_TIM_GET_COUNTER(&htim4);
		  		  		  if(__HAL_TIM_IS_TIM_COUNTING_DOWN(&htim4))
		  		  		  {
		  		  			  if(cnt4<cnt3)
								diff=cnt3-cnt4;
		  		  			  else
								diff=(65535-cnt4)+cnt3;
		  		  		  }
		  		  		  else
		  		  		  {
								if(cnt4>cnt3)
									diff=cnt4-cnt3;
								else
									diff=(65535-cnt3)+cnt4;
		  		  		  }
							sprintf(hello, "S:%5d\0", diff);
							OLED_ShowString(50,20,hello);
							dir = __HAL_TIM_IS_TIM_COUNTING_DOWN(&htim4);
							sprintf(hello, "LD:%2d\0", dir);
							OLED_ShowString(10,20,hello);
							cnt3=__HAL_TIM_GET_COUNTER(&htim4);
							tick=HAL_GetTick();
							totaldist+=diff;
		  		  		}
					}
/*					osDelay(200);
					osDelay(1000);*/
					__HAL_TIM_SetCompare(&htim8, TIM_CHANNEL_3, 0);
					if(dist==1 ||dist==2)
					{
						osDelay(1000);
					}
		  		  	  	  break;
		  	  	case 26 :

					totaldist=0;
					diff=0;
					cnt3=__HAL_TIM_GET_COUNTER(&htim4);

					HAL_GPIO_WritePin(GPIOE, CIN1_Pin, GPIO_PIN_RESET);
					HAL_GPIO_WritePin(CIN2_GPIO_Port, CIN2_Pin, GPIO_PIN_SET);
					__HAL_TIM_SetCompare(&htim8, TIM_CHANNEL_3, 800);
					tick=HAL_GetTick();
					temp=tickbaseval*0.6;
					while(totaldist<temp)
					{
					  if(HAL_GetTick()-tick>50L){
						  cnt4=__HAL_TIM_GET_COUNTER(&htim4);
						  if(__HAL_TIM_IS_TIM_COUNTING_DOWN(&htim4))
						  {
							  if(cnt4<cnt3)
								diff=cnt3-cnt4;
							  else
								diff=(65535-cnt4)+cnt3;
						  }
						  else
						  {
								if(cnt4>cnt3)
									diff=cnt4-cnt3;
								else
									diff=(65535-cnt3)+cnt4;
						  }
							sprintf(hello, "S:%5d\0", diff);
							OLED_ShowString(50,20,hello);
							dir = __HAL_TIM_IS_TIM_COUNTING_DOWN(&htim4);
							sprintf(hello, "LD:%2d\0", dir);
							OLED_ShowString(10,20,hello);
							cnt3=__HAL_TIM_GET_COUNTER(&htim4);
							tick=HAL_GetTick();
							totaldist+=diff;
						}
					}
					__HAL_TIM_SetCompare(&htim8, TIM_CHANNEL_3, 0);
		  	  		break;
	  	  	  	case 21  :

	  	  	  			  osDelay(100);
		  		  	  	  HAL_GPIO_WritePin(GPIOE, CIN1_Pin, GPIO_PIN_RESET);
		  		  	  	  HAL_GPIO_WritePin(CIN2_GPIO_Port, CIN2_Pin, GPIO_PIN_SET);
		  		  	  	  __HAL_TIM_SetCompare(&htim8, TIM_CHANNEL_3, 1500);
		  		  	  	  osDelay(dist*44);
		  		  	  __HAL_TIM_SetCompare(&htim8, TIM_CHANNEL_3, 0);
		  		  	  	  break;
	  	  	  	case 22  :

	  	  	  			  osDelay(100);
		  		  	  	  HAL_GPIO_WritePin(GPIOE, CIN1_Pin, GPIO_PIN_RESET);
		  		  	  	  HAL_GPIO_WritePin(CIN2_GPIO_Port, CIN2_Pin, GPIO_PIN_SET);
		  		  	  	  __HAL_TIM_SetCompare(&htim8, TIM_CHANNEL_3, 400);
		  		  	  	  osDelay(dist*37);
		  		  	      htim1.Instance->CCR4=85;
		  		  	  	  __HAL_TIM_SetCompare(&htim8, TIM_CHANNEL_3, 0);
		  		  	  	  osDelay(100);

		  		  	  	  break;
	  	  	  	case 0  :
	  	  	  			  __HAL_TIM_SetCompare(&htim8, TIM_CHANNEL_3, 0);

	  	  			      break;
	     default :
						  __HAL_TIM_SetCompare(&htim8, TIM_CHANNEL_3, 0);

						  break;
	  }
  }
  /* USER CODE END leftmotor */
}

void sensor(void *argument)
{
  /* USER CODE BEGIN sensor */
  /* Infinite loop */

		HAL_TIM_Encoder_Start(&htim5,TIM_CHANNEL_ALL);
		int cnt1,cnt2,diff;
		uint32_t tick;
		uint16_t dir;
		uint8_t hello[20];

		cnt1=__HAL_TIM_GET_COUNTER(&htim5);

		HAL_TIM_Encoder_Start(&htim4,TIM_CHANNEL_ALL);
		int cnt3,cnt4;
		uint16_t dir3;
		cnt3=__HAL_TIM_GET_COUNTER(&htim4);
		tick=HAL_GetTick();
		uint16_t raw;
		int irDist=0,temp=0;
		HAL_TIM_IC_Start_IT(&htim2, TIM_CHANNEL_3);
  for(;;)
  {

		//HAL_ADC_Start(&hadc1);
		//HAL_ADC_PollForConversion(&hadc1,HAL_MAX_DELAY);
		//raw=HAL_ADC_GetValue(&hadc1);
//		sensordist=33000/raw;
		HCSR04_Read();
		sensordist=Distance;
		sprintf(hello, "%5d\0", sensordist);

		OLED_ShowString(70,50,hello);
		osDelay(50);
	  	  //if(HAL_GetTick()-tick>1000L){
	  		  		/*cnt2=__HAL_TIM_GET_COUNTER(&htim5);
	  		  		if(__HAL_TIM_IS_TIM_COUNTING_DOWN(&htim5)){
	  		  				if(cnt2<cnt1)
	  		  					diff=cnt1-cnt2;
	  		  				else
	  		  					diff=(65535-cnt2)+cnt1;
	  		  					  		  		  }
	  		  				else{
	  		  				if(cnt2>cnt1)
	  		  					diff=cnt2-cnt1;
	  		  				else
	  		  					diff=(65535-cnt1)+cnt2;
	  		  					  		  	  	  }
	  		  				sprintf(hello, "S:%5d\0", diff);
	  		  				OLED_ShowString(50,30,hello);
	  		  				dir = __HAL_TIM_IS_TIM_COUNTING_DOWN(&htim5);
	  		  				sprintf(hello, "RD:%2d\0", dir);
	  		  				OLED_ShowString(10,30,hello);
	  		  				cnt1=__HAL_TIM_GET_COUNTER(&htim5);
	  		  				tick=HAL_GetTick();*/

/*	  		  		  	cnt4=__HAL_TIM_GET_COUNTER(&htim4);
	  		  		  	if(__HAL_TIM_IS_TIM_COUNTING_DOWN(&htim4)){
	  		  		  		  	if(cnt4<cnt3)
	  		  		  		  		diff=cnt3-cnt4;
	  		  		  		  	else
	  		  		  		  		diff=(65535-cnt4)+cnt3;
	  		  		  		  		}
	  		  		  		  	else{
	  		  		  		  		if(cnt4>cnt3)
	  		  		  		  			diff=cnt4-cnt3;
	  		  		  		  		else
	  		  		  		  			diff=(65535-cnt3)+cnt4;
	  		  		  		  		}
	  		  		  		  			  		sprintf(hello, "S:%5d\0", diff);
	  		  		  		  			  		OLED_ShowString(50,20,hello);
	  		  		  		  			  		dir = __HAL_TIM_IS_TIM_COUNTING_DOWN(&htim4);
	  		  		  		  			  		sprintf(hello, "LD:%2d\0", dir);
	  		  		  		  			  		OLED_ShowString(10,20,hello);
	  		  		  		  			  		cnt3=__HAL_TIM_GET_COUNTER(&htim4);
	  		  		  		  			  		tick=HAL_GetTick();

	  		  					  	  	  }*/

    osDelay(1);
  }
  /* USER CODE END sensor */
}

void Error_Handler(void)
{
  __disable_irq();
  while (1)
  {
  }
}

/************************ (C) COPYRIGHT STMicroelectronics *****END OF FILE****/
